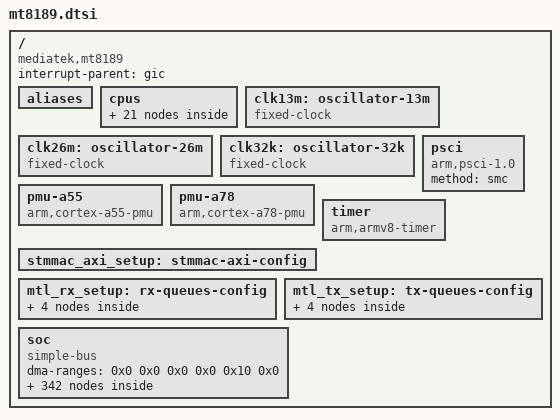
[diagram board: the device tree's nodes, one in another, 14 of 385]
// SPDX-License-Identifier: GPL-2.0+
/*
 * Copyright (c) 2024 MediaTek Inc.
 *
 */

/dts-v1/;
#include <dt-bindings/interrupt-controller/arm-gic.h>
#include <dt-bindings/interrupt-controller/irq.h>
#include <dt-bindings/memory/mediatek,mt8189-memory-port.h>
#include <dt-bindings/phy/phy.h>
#include <dt-bindings/reset/ti-syscon.h>
#include <dt-bindings/clock/mediatek,mt8189-clk.h>
#include <dt-bindings/spmi/spmi.h>
#include <dt-bindings/power/mediatek,mt8189-power.h>
#include <dt-bindings/gce/mt8189-gce.h>
#include <dt-bindings/thermal/thermal.h>

/ {
	compatible = "mediatek,mt8189";
	interrupt-parent = <&gic>;
	#address-cells = <2>;
	#size-cells = <2>;

	aliases {
		i2c0 = &i2c0;
		i2c1 = &i2c1;
		i2c2 = &i2c2;
		i2c3 = &i2c3;
		i2c4 = &i2c4;
		i2c5 = &i2c5;
		i2c6 = &i2c6;
		i2c7 = &i2c7;
		i2c8 = &i2c8;
		gce0 = &gce0;
		gce1 = &gce1;
		ovl0 = &disp_ovl0_4l;
		ovl1 = &disp_ovl1_4l;
		rdma0 = &disp_rdma0;
		rdma1 = &disp_rdma1;
		mmc0 = &mmc0;
		mmc1 = &mmc1;
		mmc2 = &mmc2;
		dvo0 = &disp_dvo0;
		dvo1 = &disp_dvo1;
		dvo2 = &disp_dvo2;
		lvds = &lvds;
	};

	cpus {
		#address-cells = <1>;
		#size-cells = <0>;

		cpu0: cpu@0 {
			device_type = "cpu";
			compatible = "arm,cortex-a55";
			reg = <0x000>;
			enable-method = "psci";
			clock-frequency = <2000000000>;
			capacity-dmips-mhz = <282>;
			performance-domains = <&performance 0>;
			cpu-idle-states = <&cpuoff_l>;
			#cooling-cells = <2>;
		};

		cpu1: cpu@100 {
			device_type = "cpu";
			compatible = "arm,cortex-a55";
			reg = <0x100>;
			enable-method = "psci";
			clock-frequency = <2000000000>;
			capacity-dmips-mhz = <282>;
			performance-domains = <&performance 0>;
			cpu-idle-states = <&cpuoff_l>;
			#cooling-cells = <2>;
		};

		cpu2: cpu@200 {
			device_type = "cpu";
			compatible = "arm,cortex-a55";
			reg = <0x200>;
			enable-method = "psci";
			clock-frequency = <2000000000>;
			capacity-dmips-mhz = <282>;
			performance-domains = <&performance 0>;
			cpu-idle-states = <&cpuoff_l>;
			#cooling-cells = <2>;
		};

		cpu3: cpu@300 {
			device_type = "cpu";
			compatible = "arm,cortex-a55";
			reg = <0x300>;
			enable-method = "psci";
			clock-frequency = <2000000000>;
			capacity-dmips-mhz = <282>;
			performance-domains = <&performance 0>;
			cpu-idle-states = <&cpuoff_l>;
			#cooling-cells = <2>;
		};

		cpu4: cpu@400 {
			device_type = "cpu";
			compatible = "arm,cortex-a55";
			reg = <0x400>;
			enable-method = "psci";
			clock-frequency = <2000000000>;
			capacity-dmips-mhz = <282>;
			performance-domains = <&performance 0>;
			cpu-idle-states = <&cpuoff_l>;
			#cooling-cells = <2>;
		};

		cpu5: cpu@500 {
			device_type = "cpu";
			compatible = "arm,cortex-a55";
			reg = <0x500>;
			enable-method = "psci";
			clock-frequency = <2000000000>;
			capacity-dmips-mhz = <282>;
			performance-domains = <&performance 0>;
			cpu-idle-states = <&cpuoff_l>;
			#cooling-cells = <2>;
		};

		cpu6: cpu@600 {
			device_type = "cpu";
			compatible = "arm,cortex-a78";
			reg = <0x600>;
			enable-method = "psci";
			clock-frequency = <2600000000>;
			capacity-dmips-mhz = <1024>;
			performance-domains = <&performance 1>;
			cpu-idle-states = <&cpuoff_b>;
			#cooling-cells = <2>;
		};

		cpu7: cpu@700 {
			device_type = "cpu";
			compatible = "arm,cortex-a78";
			reg = <0x700>;
			enable-method = "psci";
			clock-frequency = <2600000000>;
			capacity-dmips-mhz = <1024>;
			performance-domains = <&performance 1>;
			cpu-idle-states = <&cpuoff_b>;
			#cooling-cells = <2>;
		};

		cpu-map {
			cluster0 {
				core0 {
					cpu = <&cpu0>;
				};

				core1 {
					cpu = <&cpu1>;
				};

				core2 {
					cpu = <&cpu2>;
				};

				core3 {
					cpu = <&cpu3>;
				};

				core4 {
					cpu = <&cpu4>;
				};

				core5 {
					cpu = <&cpu5>;
				};

				core6 {
					cpu = <&cpu6>;
				};

				core7 {
					cpu = <&cpu7>;
				};
			};
		};

		idle-states {
			entry-method = "arm,psci";
			cpuoff_l: cpuoff-l {
				compatible = "arm,idle-state";
				arm,psci-suspend-param = <0x00010000>;
				local-timer-stop;
				entry-latency-us = <25>;
				exit-latency-us = <57>;
				min-residency-us = <5700>;
			};

			cpuoff_b: cpuoff-b {
				compatible = "arm,idle-state";
				arm,psci-suspend-param = <0x00010000>;
				local-timer-stop;
				entry-latency-us = <35>;
				exit-latency-us = <82>;
				min-residency-us = <1890>;
			};
		};
	};

	clk13m: oscillator-13m {
		compatible = "fixed-clock";
		#clock-cells = <0>;
		clock-frequency = <13000000>;
		clock-output-names = "clk13m";
	};

	clk26m: oscillator-26m {
		compatible = "fixed-clock";
		#clock-cells = <0>;
		clock-frequency = <26000000>;
		clock-output-names = "clk26m";
	};

	clk32k: oscillator-32k {
		compatible = "fixed-clock";
		#clock-cells = <0>;
		clock-frequency = <32768>;
		clock-output-names = "clk32k";
	};

	pmu-a55 {
		compatible = "arm,cortex-a55-pmu";
		interrupt-parent = <&gic>;
		interrupts = <GIC_PPI 7 IRQ_TYPE_LEVEL_HIGH &ppi_cluster0>;
	};

	pmu-a78 {
		compatible = "arm,cortex-a78-pmu";
		interrupt-parent = <&gic>;
		interrupts = <GIC_PPI 7 IRQ_TYPE_LEVEL_HIGH &ppi_cluster1>;
	};

	psci {
		compatible = "arm,psci-1.0";
		method = "smc";
	};

	timer: timer {
		compatible = "arm,armv8-timer";
		interrupt-parent = <&gic>;
		interrupts = <GIC_PPI 13 IRQ_TYPE_LEVEL_HIGH 0>,
			     <GIC_PPI 14 IRQ_TYPE_LEVEL_HIGH 0>,
			     <GIC_PPI 11 IRQ_TYPE_LEVEL_HIGH 0>,
			     <GIC_PPI 10 IRQ_TYPE_LEVEL_HIGH 0>;
		clock-frequency = <13000000>;
	};

	stmmac_axi_setup: stmmac-axi-config {
		snps,wr-osr-lmt = <0x7>;
		snps,rd-osr-lmt = <0x7>;
		snps,blen = <0 0 0 0 16 8 4>;
	};

	mtl_rx_setup: rx-queues-config {
		snps,rx-queues-to-use = <4>;
		snps,rx-sched-sp;
		queue0 {
			snps,dcb-algorithm;
			snps,map-to-dma-channel = <0x0>;
		};
		queue1 {
			snps,dcb-algorithm;
			snps,map-to-dma-channel = <0x0>;
		};
		queue2 {
			snps,dcb-algorithm;
			snps,map-to-dma-channel = <0x0>;
		};
		queue3 {
			snps,dcb-algorithm;
			snps,map-to-dma-channel = <0x0>;
		};
	};

	mtl_tx_setup: tx-queues-config {
		snps,tx-queues-to-use = <4>;
		snps,tx-sched-wrr;
		queue0 {
			snps,weight = <0x10>;
			snps,dcb-algorithm;
			snps,priority = <0x0>;
		};
		queue1 {
			snps,weight = <0x11>;
			snps,dcb-algorithm;
			snps,priority = <0x1>;
		};
		queue2 {
			snps,weight = <0x12>;
			snps,dcb-algorithm;
			snps,priority = <0x2>;
		};
		queue3 {
			snps,weight = <0x13>;
			snps,dcb-algorithm;
			snps,priority = <0x3>;
		};
	};

	soc {
		#address-cells = <2>;
		#size-cells = <2>;
		compatible = "simple-bus";
		ranges;
		dma-ranges = <0x0 0x0 0x0 0x0 0x10 0x0>;

		performance: performance-controller@108d68 {
			compatible = "mediatek,cpufreq-hw";
			reg = <0 0x00108d78 0 0x120>,
			      <0 0x00108e98 0 0x120>;
			reg-names = "performance-domain0",
				    "performance-domain1";
			#performance-domain-cells = <1>;
		};

		gic: interrupt-controller@c000000 {
			compatible = "arm,gic-v3";
			#interrupt-cells = <4>;
			#redistributor-regions = <1>;
			interrupt-parent = <&gic>;
			interrupt-controller;
			reg = <0 0x0c000000 0 0x40000>,
			      <0 0x0c040000 0 0x200000>;
			interrupts = <GIC_PPI 9 IRQ_TYPE_LEVEL_HIGH 0>;

			ppi-partitions {
				ppi_cluster0: interrupt-partition-0 {
					affinity = <&cpu0 &cpu1 &cpu2 &cpu3 &cpu4 &cpu5>;
				};

				ppi_cluster1: interrupt-partition-1 {
					affinity = <&cpu6 &cpu7>;
				};
			};
		};

		dbgao_clk: syscon@d01a000 {
			compatible = "mediatek,mt8189-dbg_ao", "syscon";
			reg = <0 0xd01a000 0 0x1000>;
			#clock-cells = <1>;
		};

		dem_clk: syscon@d0a0000 {
			compatible = "mediatek,mt8189-dem", "syscon";
			reg = <0 0xd0a0000 0 0x1000>;
			#clock-cells = <1>;
		};

		topckgen_clk: syscon@10000000 {
			compatible = "mediatek,mt8189-topckgen", "syscon";
			reg = <0 0x10000000 0 0x1000>;
			#clock-cells = <1>;
		};

		infracfg_ao_clk: syscon@10001000 {
			compatible = "mediatek,mt8189-infra_ao", "syscon";
			reg = <0 0x10001000 0 0x1000>;
			#clock-cells = <1>;
		};

		pio: pinctrl@10005000 {
			compatible = "mediatek,mt8189-pinctrl";
			reg = <0 0x10005000 0 0x1000>,
			      <0 0x11b50000 0 0x1000>,
			      <0 0x11c50000 0 0x1000>,
			      <0 0x11c60000 0 0x1000>,
			      <0 0x11d20000 0 0x1000>,
			      <0 0x11d30000 0 0x1000>,
			      <0 0x11d40000 0 0x1000>,
			      <0 0x11e20000 0 0x1000>,
			      <0 0x11e30000 0 0x1000>,
			      <0 0x11f20000 0 0x1000>;
			reg-names = "gpio_base",
						"iocfg_lm_base",
						"iocfg_rb0_base",
						"iocfg_rb1_base",
						"iocfg_bm0_base",
						"iocfg_bm1_base",
						"iocfg_bm2_base",
						"iocfg_lt0_base",
						"iocfg_lt1_base",
						"iocfg_rt_base";
			gpio-controller;
			#gpio-cells = <2>;
			gpio-ranges = <&pio 0 0 182>;
			interrupt-controller;
			#interrupt-cells = <2>;
			mediatek,eint = <&eint>;
		};

		apmixedsys_clk: syscon@1000c000 {
			compatible = "mediatek,mt8189-apmixedsys", "syscon";
			reg = <0 0x1000c000 0 0x1000>;
			#clock-cells = <1>;
		};

		usb_dp_selector: usb-dp-selector@10011018 {
			compatible = "mediatek,usb_dp_selector";
			reg = <0 0x10011018 0 0x4>;
			reg-names = "usb_dp_reg";
			mediatek,uds-ver = <3>;
			status = "disabled";
		};

		usb_dp_selector_p3: usb-dp-selector@10011034 {
			compatible = "mediatek,usb_dp_selector";
			reg = <0 0x10011034 0 0x4>;
			reg-names = "usb_dp_reg";
			mediatek,uds-ver = <4>;
			status = "disabled";
		};

		emicfg_ao_mem_clk: syscon@10270000 {
			compatible = "mediatek,mt8189-emicfg_ao_mem", "syscon";
			reg = <0 0x10270000 0 0x1000>;
		};

		infra_iommu_m4: infra-iommu@10330000 {
			compatible = "mediatek,mt8189-iommu-infra";
			reg = <0 0x10330000 0 0x1000>;
			interrupts = <GIC_SPI 553 IRQ_TYPE_LEVEL_HIGH 0>;
			clocks = <&clk26m>;
			clock-names = "bclk";
			#iommu-cells = <1>;
		};

		infra_iommu_m7: infra-iommu@1033a000 {
			compatible = "mediatek,mt8189-iommu-infra";
			reg = <0 0x1033a000 0 0x1000>;
			interrupts = <GIC_SPI 543 IRQ_TYPE_LEVEL_HIGH 0>;
			clocks = <&clk26m>;
			clock-names = "bclk";
			#iommu-cells = <1>;
		};

		pericfg_ao_clk: syscon@11036000 {
			compatible = "mediatek,mt8189-peri_ao", "syscon";
			reg = <0 0x11036000 0 0x1000>;
			#clock-cells = <1>;
		};

		uart0: serial@11001000 {
			compatible = "mediatek,mt6577-uart";
			reg = <0 0x11001000 0 0x1000>;
			interrupts = <GIC_SPI 397 IRQ_TYPE_LEVEL_HIGH 0>;
			clocks = <&clk26m>, <&pericfg_ao_clk CLK_PERAO_UART0>;
			clock-names = "baud", "bus";
			status = "disabled";
		};

		uart1: serial@11002000 {
			compatible = "mediatek,mt6577-uart";
			reg = <0 0x11002000 0 0x1000>;
			interrupts = <GIC_SPI 398 IRQ_TYPE_LEVEL_HIGH 0>;
			clocks = <&clk26m>, <&pericfg_ao_clk CLK_PERAO_UART1>;
			clock-names = "baud", "bus";
			dmas = <&apdma 2 &apdma 3>;
			dma-names = "tx", "rx";
			uart-line = <1>;
			status = "disabled";
		};

		uart2: serial@11003000 {
			compatible = "mediatek,mt6577-uart";
			reg = <0 0x11003000 0 0x1000>;
			interrupts = <GIC_SPI 399 IRQ_TYPE_LEVEL_HIGH 0>;
			clocks = <&clk26m>, <&pericfg_ao_clk CLK_PERAO_UART2>;
			clock-names = "baud", "bus";
			dmas = <&apdma 4 &apdma 5>;
			dma-names = "tx", "rx";
			uart-line = <2>;
			status = "disabled";
		};

		uart3: serial@11004000 {
			compatible = "mediatek,mt6577-uart";
			reg = <0 0x11004000 0 0x1000>;
			interrupts = <GIC_SPI 457 IRQ_TYPE_LEVEL_HIGH 0>;
			clocks = <&clk26m>, <&pericfg_ao_clk CLK_PERAO_UART3>;
			clock-names = "baud", "bus";
			dmas = <&apdma 6 &apdma 7>;
			dma-names = "tx", "rx";
			uart-line = <3>;
			status = "disabled";
		};

		afe_clk: syscon@11050000 {
			compatible = "mediatek,mt8189-audiosys", "syscon";
			reg = <0 0x11050000 0 0x1000>;
			#clock-cells = <1>;
		};

		afe: mt8189-afe-pcm@11050000 {
			compatible = "mediatek,mt8189-afe-pcm";
			reg = <0 0x11050000 0 0x10000>;
			interrupts = <GIC_SPI 392 IRQ_TYPE_LEVEL_HIGH 0>;
			power-domains = <&scpsys MT8189_POWER_DOMAIN_AUDIO>;
			memory-region = <&afe_dma_mem_reserved>;
			clocks = <&topckgen_clk CLK_TOP_AUD_INTBUS_SEL>,
				 <&topckgen_clk CLK_TOP_AUD_ENGEN1_SEL>,
				 <&topckgen_clk CLK_TOP_AUD_ENGEN2_SEL>,
				 <&topckgen_clk CLK_TOP_AUDIO_H_SEL>,
				 <&topckgen_clk CLK_TOP_APLL1>,
				 <&topckgen_clk CLK_TOP_APLL2>,
				 <&topckgen_clk CLK_TOP_APLL1_D4>,
				 <&topckgen_clk CLK_TOP_APLL2_D4>,
				 <&topckgen_clk CLK_TOP_APLL12_CK_DIV_I2SIN0>,
				 <&topckgen_clk CLK_TOP_APLL12_CK_DIV_I2SIN1>,
				 <&topckgen_clk CLK_TOP_APLL12_CK_DIV_I2SOUT0>,
				 <&topckgen_clk CLK_TOP_APLL12_CK_DIV_I2SOUT1>,
				 <&topckgen_clk CLK_TOP_APLL12_CK_DIV_FMI2S>,
				 <&topckgen_clk CLK_TOP_APLL12_CK_DIV_TDMOUT_M>,
				 <&topckgen_clk CLK_TOP_APLL12_CK_DIV_TDMOUT_B>,
				 <&topckgen_clk CLK_TOP_AUD_1_SEL>,
				 <&topckgen_clk CLK_TOP_AUD_2_SEL>,
				 <&topckgen_clk CLK_TOP_APLL_I2SIN0_MCK_SEL>,
				 <&topckgen_clk CLK_TOP_APLL_I2SIN1_MCK_SEL>,
				 <&topckgen_clk CLK_TOP_APLL_I2SOUT0_MCK_SEL>,
				 <&topckgen_clk CLK_TOP_APLL_I2SOUT1_MCK_SEL>,
				 <&topckgen_clk CLK_TOP_APLL_FMI2S_MCK_SEL>,
				 <&topckgen_clk CLK_TOP_APLL_TDMOUT_MCK_SEL>,
				 <&topckgen_clk CLK_TOP_TCK_26M_MX9>,
				 <&pericfg_ao_clk CLK_PERAO_AUDIO0>,
				 <&pericfg_ao_clk CLK_PERAO_AUDIO1>,
				 <&pericfg_ao_clk CLK_PERAO_AUDIO2>;
			clock-names = "top_aud_intbus",
				      "top_aud_eng1",
				      "top_aud_eng2",
				      "top_aud_h",
				      "apll1",
				      "apll2",
				      "apll1_d4",
				      "apll2_d4",
				      "apll12_div_i2sin0",
				      "apll12_div_i2sin1",
				      "apll12_div_i2sout0",
				      "apll12_div_i2sout1",
				      "apll12_div_fmi2s",
				      "apll12_div_tdmout_m",
				      "apll12_div_tdmout_b",
				      "top_apll1",
				      "top_apll2",
				      "top_i2sin0",
				      "top_i2sin1",
				      "top_i2sout0",
				      "top_i2sout1",
				      "top_fmi2s",
				      "top_dptx",
				      "clk26m",
				      "aud_slv_ck_peri",
				      "aud_mst_ck_peri",
				      "aud_intbus_ck_peri";
			mediatek,apmixedsys = <&apmixedsys_clk>;
			mediatek,topckgen = <&topckgen_clk>;
			status = "disabled";
		};

		sound: sound {
			mediatek,platform = <&afe>;
			status = "disabled";
		};

		sspm: sspm@1c300000 {
			compatible = "mediatek,sspm";
			reg = <0 0x1c300000 0 0x2c000>,
			      <0 0x1c340000 0 0x10000>,
			      <0 0x1c380000 0 0x80>;

			reg-names = "sspm_base",
				    "cfgreg",
				    "mbox_share";

			interrupts = <GIC_SPI 508 IRQ_TYPE_LEVEL_HIGH 0>;
			interrupt-names = "ipc";
			memory-region = <&sspm_resv_mem>;
			sspm-res-ram-start = <0x0>;
			sspm-res-ram-size = <0x110000>; /* 1M + 64K */

			sspm-share-region-base = <0x24000>; /* 144K */
			sspm-share-region-size = <0x8000>; /* 32K */
			status = "disabled";
		};

		ssram@1c350000 {
			compatible = "mmio-sram";
			reg = <0x0 0x1c350000 0x0 0x80>;

			#address-cells = <1>;
			#size-cells = <1>;
			ranges = <0 0x0 0x1c350000 0x80>;

			scmi_tx_shmem: tiny-mbox@0 {
				compatible = "arm,scmi-shmem";
				reg = <0x0 0x80>;
			};
		};

		ssram@1c360000 {
			compatible = "mmio-sram";
			reg = <0x0 0x1c360000 0x0 0x80>;

			#address-cells = <1>;
			#size-cells = <1>;
			ranges = <0 0x0 0x1c360000 0x80>;

			scmi_rx_shmem: tiny-mbox@1 {
				compatible = "arm,scmi-shmem";
				reg = <0x0 0x80>;
			};
		};

		tinysys_mbox: tinysys-mbox@1c351000 {
			compatible = "mediatek,tinysys_mbox";
			reg = <0 0x1c351000 0 0x1000>,
			      <0 0x1c361000 0 0x1000>;
			/* for profiling */
			shmem = <&scmi_tx_shmem>, <&scmi_rx_shmem>;
			interrupts = <GIC_SPI 509 IRQ_TYPE_LEVEL_HIGH 0>,
				     <GIC_SPI 510 IRQ_TYPE_LEVEL_HIGH 0>;
			#mbox-cells = <1>;
		};

		ssusb: usb0@11201000 {
			compatible = "mediatek,mtu3";
			reg = <0 0x11201000 0 0x2e00>,
			      <0 0x11203e00 0 0x0100>;
			reg-names = "mac", "ippc";
			interrupts = <GIC_SPI 384 IRQ_TYPE_LEVEL_HIGH 0>;
			phy-cells = <1>;
			phys = <&u2port0 PHY_TYPE_USB2>,
			       <&u3port0 PHY_TYPE_USB3>;
			assigned-clocks = <&topckgen_clk CLK_TOP_USB_TOP_P0_SEL>;
			assigned-clock-parents = <&topckgen_clk CLK_TOP_UNIVPLL_D5_D4>;
			clocks = <&pericfg_ao_clk CLK_PERAO_SSUSB0_XHCI>,
				 <&pericfg_ao_clk CLK_PERAO_SSUSB0_SYS>,
				 <&pericfg_ao_clk CLK_PERAO_SSUSB0_H>,
				 <&pericfg_ao_clk CLK_PERAO_SSUSB0_F>,
				 <&pericfg_ao_clk CLK_PERAO_SSUSB0_REF>,
				 <&pericfg_ao_clk CLK_PERAO_SSUSB0_FRMCNT>;
			clock-names = "xhci_ck",
				      "sys_ck",
				      "mcu_ck",
				      "dma_ck",
				      "ref_ck",
				      "frmcnt_ck";
			#address-cells = <2>;
			#size-cells = <2>;
			ranges;
			dr_mode = "otg";
			mediatek,syscon-wakeup = <&pericfg_ao_clk 0x214 103>;
			usb-role-switch;
			xhci0: xhci0@11200000 {
				compatible = "mediatek,mtk-xhci";
				reg = <0 0x11200000 0 0x1000>;
				reg-names = "mac";
				interrupts = <GIC_SPI 385 IRQ_TYPE_LEVEL_HIGH 0>;
				assigned-clocks = <&topckgen_clk CLK_TOP_USB_XHCI_P0_SEL>;
				assigned-clock-parents = <&topckgen_clk CLK_TOP_UNIVPLL_D5_D4>;
				clocks = <&pericfg_ao_clk CLK_PERAO_SSUSB0_XHCI>,
					 <&pericfg_ao_clk CLK_PERAO_SSUSB0_SYS>,
					 <&pericfg_ao_clk CLK_PERAO_SSUSB0_H>,
					 <&pericfg_ao_clk CLK_PERAO_SSUSB0_F>,
					 <&pericfg_ao_clk CLK_PERAO_SSUSB0_REF>;
				clock-names = "xhci_ck",
					      "sys_ck",
					      "mcu_ck",
					      "dma_ck",
					      "ref_ck";
			};
		};

		xhci1: xhci1@11210000 {
			compatible = "mediatek,mtk-xhci";
			reg = <0 0x11210000 0 0x1000>,
			      <0 0x11213e00 0 0x0100>;
			reg-names = "mac", "ippc";
			interrupts = <GIC_SPI 386 IRQ_TYPE_LEVEL_HIGH 0>;
			phy-cells = <1>;
			phys = <&u2port1 PHY_TYPE_USB2>;
			assigned-clocks = <&topckgen_clk CLK_TOP_USB_TOP_P1_SEL>,
					  <&topckgen_clk CLK_TOP_USB_XHCI_P1_SEL>;
			assigned-clock-parents = <&topckgen_clk CLK_TOP_UNIVPLL_D5_D4>,
						 <&topckgen_clk CLK_TOP_UNIVPLL_D5_D4>;
			clocks = <&pericfg_ao_clk CLK_PERAO_SSUSB1_XHCI>,
				 <&pericfg_ao_clk CLK_PERAO_SSUSB1_SYS>,
				 <&pericfg_ao_clk CLK_PERAO_SSUSB1_H>,
				 <&pericfg_ao_clk CLK_PERAO_SSUSB1_F>,
				 <&pericfg_ao_clk CLK_PERAO_SSUSB1_REF>,
				 <&pericfg_ao_clk CLK_PERAO_SSUSB1_FRMCNT>;
			clock-names = "xhci_ck",
				      "sys_ck",
				      "mcu_ck",
				      "dma_ck",
				      "ref_ck",
				      "frmcnt_ck";
			power-domains = <&scpsys MT8189_POWER_DOMAIN_SSUSB>;
			mediatek,syscon-wakeup = <&pericfg_ao_clk 0x21c 107>;
			#address-cells = <2>;
			#size-cells = <2>;
			status = "disabled";
		};

		xhci2: xhci2@11220000 {
			compatible = "mediatek,mtk-xhci";
			reg = <0 0x11220000 0 0x1000>,
			      <0 0x11223e00 0 0x0100>;
			reg-names = "mac", "ippc";
			interrupts = <GIC_SPI 472 IRQ_TYPE_LEVEL_HIGH 0>;
			phy-cells = <1>;
			phys = <&u2port2 PHY_TYPE_USB2>;
			assigned-clocks = <&topckgen_clk CLK_TOP_USB_TOP_P2_SEL>,
					  <&topckgen_clk CLK_TOP_USB_XHCI_P2_SEL>;
			assigned-clock-parents = <&topckgen_clk CLK_TOP_UNIVPLL_D5_D4>,
						 <&topckgen_clk CLK_TOP_UNIVPLL_D5_D4>;
			clocks = <&pericfg_ao_clk CLK_PERAO_SSUSB2_XHCI>,
				 <&pericfg_ao_clk CLK_PERAO_SSUSB2_SYS>,
				 <&pericfg_ao_clk CLK_PERAO_SSUSB2_H>,
				 <&pericfg_ao_clk CLK_PERAO_SSUSB2_F>,
				 <&pericfg_ao_clk CLK_PERAO_SSUSB2_REF>,
				 <&pericfg_ao_clk CLK_PERAO_SSUSB2_FRMCNT>;
			clock-names = "xhci_ck",
				      "sys_ck",
				      "mcu_ck",
				      "dma_ck",
				      "ref_ck",
				      "frmcnt_ck";
			power-domains = <&scpsys MT8189_POWER_DOMAIN_SSUSB>;
			mediatek,syscon-wakeup = <&pericfg_ao_clk 0x27c 107>;
			#address-cells = <2>;
			#size-cells = <2>;
			status = "disabled";
		};

		xhci3: xhci3@11260000 {
			compatible = "mediatek,mtk-xhci";
			reg = <0 0x11260000 0 0x2e00>,
			      <0 0x11263e00 0 0x0100>;
			reg-names = "mac", "ippc";
			interrupts = <GIC_SPI 473 IRQ_TYPE_LEVEL_HIGH 0>;
			phy-cells = <1>;
			phys = <&u2port3 PHY_TYPE_USB2>,
			       <&u3port3 PHY_TYPE_USB3>;
			assigned-clocks = <&topckgen_clk CLK_TOP_USB_TOP_P3_SEL>,
					  <&topckgen_clk CLK_TOP_USB_XHCI_P3_SEL>;
			assigned-clock-parents = <&topckgen_clk CLK_TOP_UNIVPLL_D5_D4>,
						 <&topckgen_clk CLK_TOP_UNIVPLL_D5_D4>;
			clocks = <&pericfg_ao_clk CLK_PERAO_SSUSB3_XHCI>,
				 <&pericfg_ao_clk CLK_PERAO_SSUSB3_SYS>,
				 <&pericfg_ao_clk CLK_PERAO_SSUSB3_H>,
				 <&pericfg_ao_clk CLK_PERAO_SSUSB3_F>,
				 <&pericfg_ao_clk CLK_PERAO_SSUSB3_REF>,
				 <&pericfg_ao_clk CLK_PERAO_SSUSB3_FRMCNT>;
			clock-names = "xhci_ck",
				      "sys_ck",
				      "mcu_ck",
				      "dma_ck",
				      "ref_ck",
				      "frmcnt_ck";
			power-domains = <&scpsys MT8189_POWER_DOMAIN_SSUSB>;
			mediatek,syscon-wakeup = <&pericfg_ao_clk 0x284 107>;
			#address-cells = <2>;
			#size-cells = <2>;
			status = "disabled";
		};

		xhci4: xhci4@11270000 {
			compatible = "mediatek,mtk-xhci";
			reg = <0 0x11270000 0 0x1000>,
			      <0 0x11273e00 0 0x0100>;
			reg-names = "mac", "ippc";
			interrupts = <GIC_SPI 474 IRQ_TYPE_LEVEL_HIGH 0>;
			phy-cells = <1>;
			phys = <&u2port4 PHY_TYPE_USB2>;
			assigned-clocks = <&topckgen_clk CLK_TOP_USB_TOP_P4_SEL>,
					  <&topckgen_clk CLK_TOP_USB_XHCI_P4_SEL>;
			assigned-clock-parents = <&topckgen_clk CLK_TOP_UNIVPLL_D5_D4>,
						 <&topckgen_clk CLK_TOP_UNIVPLL_D5_D4>;
			clocks = <&pericfg_ao_clk CLK_PERAO_SSUSB4_XHCI>,
				 <&pericfg_ao_clk CLK_PERAO_SSUSB4_SYS>,
				 <&pericfg_ao_clk CLK_PERAO_SSUSB4_H>,
				 <&pericfg_ao_clk CLK_PERAO_SSUSB4_F>,
				 <&pericfg_ao_clk CLK_PERAO_SSUSB4_REF>,
				 <&pericfg_ao_clk CLK_PERAO_SSUSB4_FRMCNT>;
			clock-names = "xhci_ck",
				      "sys_ck",
				      "mcu_ck",
				      "dma_ck",
				      "ref_ck",
				      "frmcnt_ck";
			#address-cells = <2>;
			#size-cells = <2>;
			mediatek,syscon-wakeup = <&pericfg_ao_clk 0x28c 107>;
			status = "disabled";
		};

		mmc0: mmc@11230000 {
			compatible = "mediatek,mt8196-mmc";
			reg = <0 0x11230000 0 0x10000>,
			      <0 0x11e70000 0 0x1000>;
			interrupts = <GIC_SPI 387 IRQ_TYPE_LEVEL_HIGH 0>;
			clocks = <&topckgen_clk CLK_TOP_MSDC50_0_SEL>,
				<&topckgen_clk CLK_TOP_MSDC50_0_HCLK_SEL>,
				<&pericfg_ao_clk CLK_PERAO_MSDC0>,
				<&pericfg_ao_clk CLK_PERAO_MSDC0_H>,
				<&topckgen_clk CLK_TOP_MSDC50_0_SEL>,
				<&pericfg_ao_clk CLK_PERAO_MSDC0_SLV_H>,
				<&pericfg_ao_clk CLK_PERAO_MSDC0_MST_F>;
			clock-names = "source", "bus_clk", "source_cg", "hclk",
					"crypto", "pclk_cg", "axi_cg";
			status = "disabled";
		};

		mmc1: mmc@11240000 {
			compatible = "mediatek,mt8196-mmc";
			reg = <0 0x11240000 0 0x1000>,
			      <0 0x11d80000 0 0x1000>;
			interrupts = <GIC_SPI 388 IRQ_TYPE_LEVEL_HIGH 0>;
			clocks = <&topckgen_clk CLK_TOP_MSDC30_1_SEL>,
				<&topckgen_clk CLK_TOP_MSDC30_1_HCLK_SEL>,
				<&pericfg_ao_clk CLK_PERAO_MSDC1>,
				<&pericfg_ao_clk CLK_PERAO_MSDC1_H>,
				<&pericfg_ao_clk CLK_PERAO_MSDC1_SLV_H>,
				<&pericfg_ao_clk CLK_PERAO_MSDC1_MST_F>;
			clock-names = "source", "bus_clk", "source_cg", "hclk",
					"pclk_cg", "axi_cg";
			status = "disabled";
		};

		mmc2: mmc@11250000 {
			compatible = "mediatek,mt8196-mmc";
			reg = <0 0x11250000 0 0x1000>,
			      <0 0x11f70000 0 0x1000>;
			interrupts = <GIC_SPI 389 IRQ_TYPE_LEVEL_HIGH 0>;
			clocks = <&topckgen_clk CLK_TOP_MSDC30_2_SEL>,
				<&topckgen_clk CLK_TOP_MSDC_MACRO_2P_SEL>,
				<&pericfg_ao_clk CLK_PERAO_MSDC2_H>,
				<&pericfg_ao_clk CLK_PERAO_MSDC2>,
				<&pericfg_ao_clk CLK_PERAO_MSDC2_MST_F>,
				<&pericfg_ao_clk CLK_PERAO_MSDC2_SLV_H>;
			clock-names = "source", "bus_clk", "hclk", "source_cg",
					"pclk_cg", "sys_cg";
			status = "disabled";
		};

		nor_flash: spi@11018000 {
			compatible = "mediatek,mt8186-nor",
						"mediatek,mt8189-nor";
			reg = <0 0x11018000 0 0x1000>;
			clocks = <&topckgen_clk CLK_TOP_SFLASH_SEL>,
				 <&pericfg_ao_clk CLK_PERAO_SFLASH>,
				 <&pericfg_ao_clk CLK_PERAO_SFLASH_F>,
				 <&pericfg_ao_clk CLK_PERAO_SFLASH_H>,
				 <&pericfg_ao_clk CLK_PERAO_SFLASH_P>;
			clock-names = "spi", "sf", "axi_f", "axi_h", "axi_p";
			assigned-clocks = <&topckgen_clk CLK_TOP_SFLASH_SEL>;
			assigned-clock-parents = <&topckgen_clk CLK_TOP_UNIVPLL_D6_D8>;
			interrupts = <GIC_SPI 390 IRQ_TYPE_LEVEL_HIGH 0>;
			#address-cells = <1>;
			#size-cells = <0>;
			status = "disabled";
		};

		ufsphy: ufsphy@112a0000 {
			compatible = "mediatek,mt8183-ufsphy";
			reg = <0 0x112a0000 0 0x10000>;
			#phy-cells = <0>;
			mphy-ver = <1>;
			status = "disabled";
		};

		ufshci: ufshci@112b0000 {
			compatible = "mediatek,mt8183-ufshci";
			reg = <0 0x112b0000 0 0x2300>;
			phys = <&ufsphy>;
			interrupts = <GIC_SPI 393 IRQ_TYPE_LEVEL_HIGH 0>;

			clocks =
				<&topckgen_clk CLK_TOP_U_SEL>,
				<&topckgen_clk CLK_TOP_AES_UFSFDE_SEL>,
				<&topckgen_clk CLK_TOP_U_MBIST_SEL>,
				<&ufscfg_ao_reg_clk CLK_UFSCFG_AO_REG_UNIPRO_TX_SYM>,
				<&ufscfg_ao_reg_clk CLK_UFSCFG_AO_REG_UNIPRO_RX_SYM0>,
				<&ufscfg_ao_reg_clk CLK_UFSCFG_AO_REG_UNIPRO_RX_SYM1>,
				<&ufscfg_ao_reg_clk CLK_UFSCFG_AO_REG_UNIPRO_SYS>,
				<&ufscfg_ao_reg_clk CLK_UFSCFG_AO_REG_U_SAP_CFG>,
				<&ufscfg_ao_reg_clk CLK_UFSCFG_AO_REG_U_PHY_TOP_AHB_S_BUS>,
				<&ufscfg_pdn_reg_clk CLK_UFSCFG_REG_UFSHCI_UFS>,
				<&ufscfg_pdn_reg_clk CLK_UFSCFG_REG_UFSHCI_AES>,
				<&ufscfg_pdn_reg_clk CLK_UFSCFG_REG_UFSHCI_U_AHB>,
				<&ufscfg_pdn_reg_clk CLK_UFSCFG_REG_UFSHCI_U_AXI>;

			clock-names =
				"ufs_sel",
				"ufs_fde",
				"ufs_mbist",
				"unipro_tx_sym",
				"unipro_rx_sym0",
				"unipro_rx_sym1",
				"unipro_sys",
				"unipro_phy_sap",
				"phy_top_ahb_s_bus",
				"ufshci_ufs",
				"ufshci_aes",
				"ufshci_ufs_ahb",
				"ufshci_aes_axi";

			freq-table-hz =
				<0 0>,
				<0 0>,
				<0 0>,
				<0 0>,
				<0 0>,
				<0 0>,
				<0 0>,
				<0 0>,
				<0 0>,
				<0 0>,
				<0 0>,
				<0 0>,
				<0 0>;

			vcc-supply = <&mt6359_vemc_1_ldo_reg>;
			vccq-supply = <&mt6359_vio18_ldo_reg>;
			vccq2-supply = <&mt6359_vufs_ldo_reg>;

			resets =	<&ufscfgpdn_rst 0>,
					<&ufscfgpdn_rst 1>,
					<&ufscfgpdn_rst 2>;
			reset-names =	"unipro_rst",
					"crypto_rst",
					"hci_rst";

			mediatek,ufs-qos;
			mediatek,ufs-mphy-debug;
			mediatek,ufs-disable-mcq;
			mediatek,ufs-rtff-mtcmos;
			mediatek,ufs-bypass-vccqx-lpm;
			status = "disabled";
		};

		ufscfg_ao_reg_clk: syscon@112b8000 {
			compatible = "mediatek,mt8189-ufscfg_ao", "syscon", "simple-mfd";
			reg = <0 0x112b8000 0 0x1000>;
			#clock-cells = <1>;

			ufscfgao_rst: reset-controller {
				compatible = "ti,syscon-reset";
				#reset-cells = <1>;

				ti,reset-bits = <
					/* ufs mphy reset */
					/* 8: mphy */
					0x48  8 0x4c  8 0 0
					(ASSERT_SET | DEASSERT_SET | STATUS_NONE)
					>;
			};
		};

		ufscfg_pdn_reg_clk: syscon@112bb000 {
			compatible = "mediatek,mt8189-ufscfg_pdn", "syscon", "simple-mfd";
			reg = <0 0x112bb000 0 0x1000>;
			#clock-cells = <1>;

			ufscfgpdn_rst: reset-controller {
				compatible = "ti,syscon-reset";
				#reset-cells = <1>;

				ti,reset-bits = <
					/* ufs ufschi/crypto/unipro reset */
					/* 0: unipro */
					0x48  0 0x4c  0 0 0
					(ASSERT_SET | DEASSERT_SET | STATUS_NONE)
					/* 1: ufs-crypto */
					0x48  1 0x4c  1 0 0
					(ASSERT_SET | DEASSERT_SET | STATUS_NONE)
					/* 2: ufshci */
					0x48  2 0x4c  2 0 0
					(ASSERT_SET | DEASSERT_SET | STATUS_NONE)
					>;
			};
		};

		apdma: dma-controller@11300b00 {
			compatible = "mediatek,mt6577-uart-dma";
			reg = <0 0x11300b00 0 0x80>,
			      <0 0x11300b80 0 0x80>,
			      <0 0x11300c00 0 0x80>,
			      <0 0x11300c80 0 0x80>,
			      <0 0x11300d00 0 0x80>,
			      <0 0x11300d80 0 0x80>,
			      <0 0x11300e00 0 0x80>,
			      <0 0x11300e80 0 0x80>;
			interrupts = <GIC_SPI 432 IRQ_TYPE_LEVEL_HIGH 0>,
				     <GIC_SPI 433 IRQ_TYPE_LEVEL_HIGH 0>,
				     <GIC_SPI 434 IRQ_TYPE_LEVEL_HIGH 0>,
				     <GIC_SPI 435 IRQ_TYPE_LEVEL_HIGH 0>,
				     <GIC_SPI 436 IRQ_TYPE_LEVEL_HIGH 0>,
				     <GIC_SPI 437 IRQ_TYPE_LEVEL_HIGH 0>,
				     <GIC_SPI 438 IRQ_TYPE_LEVEL_HIGH 0>,
				     <GIC_SPI 439 IRQ_TYPE_LEVEL_HIGH 0>;
			clocks = <&pericfg_ao_clk CLK_PERAO_DMA_B>;
			clock-names = "apdma";
			dma-requests = <8>;
			#dma-cells = <1>;
		};

		u3phy3: t-phy3@11b00000 {
			compatible = "mediatek,generic-tphy-v2";
			reg = <0 0x11b00000 0 0x700>;
			#address-cells = <2>;
			#size-cells = <2>;
			ranges;

			u2port3: usb2-phy3@11b00000 {
				reg = <0 0x11b00000 0 0x400>;
				clocks = <&topckgen_clk CLK_TOP_USB2_PHY_RF_P3_EN>;
				clock-names = "ref";
				#phy-cells = <1>;
			};

			u3port3: usb3-phy3@11b00700 {
				reg = <0 0x11b00700 0 0x700>;
				clocks = <&topckgen_clk CLK_TOP_USB2_PHY_RF_P3_EN>;
				clock-names = "ref";
				#phy-cells = <1>;
				mediatek,keep-u3-phy-power;
			};
		};

		u2phy4: xs-phy4@11b10000 {
			compatible = "mediatek,xsphy";
			#address-cells = <2>;
			#size-cells = <2>;
			ranges;

			u2port4: usb2-phy4@11b10000 {
				reg = <0 0x11b10000 0 0x400>;
				clocks = <&topckgen_clk CLK_TOP_USB2_PHY_RF_P4_EN>;
				clock-names = "ref";
				#phy-cells = <1>;
			};
		};

		imp_iic_wrap_ws_clk: syscon@11b21000 {
			compatible = "mediatek,mt8189-iic_wrap_ws", "syscon";
			reg = <0 0x11b21000 0 0x1000>;
			#clock-cells = <1>;
		};

		imp_iic_wrap_e_clk: syscon@11c22000 {
			compatible = "mediatek,mt8189-iic_wrap_e", "syscon";
			reg = <0 0x11c22000 0 0x1000>;
			#clock-cells = <1>;
		};

		imp_iic_wrap_s_clk: syscon@11d74000 {
			compatible = "mediatek,mt8189-iic_wrap_s", "syscon";
			reg = <0 0x11d74000 0 0x1000>;
			#clock-cells = <1>;
		};

		u3phy0: xs-phy0@11e80000 {
			compatible = "mediatek,xsphy";
			reg = <0 0x11e83000 0 0x200>;
			#address-cells = <2>;
			#size-cells = <2>;
			ranges;

			u2port0: usb2-phy0@11e80000 {
				reg = <0 0x11e80000 0 0x400>;
				clocks = <&topckgen_clk CLK_TOP_USB2_PHY_RF_P0_EN>;
				clock-names = "ref";
				#phy-cells = <1>;
			};

			u3port0: usb3-phy0@11e83000 {
				reg = <0 0x11e83400 0 0x500>;
				clocks = <&topckgen_clk CLK_TOP_USB2_PHY_RF_P0_EN>;
				clock-names = "ref";
				#phy-cells = <1>;
			};
		};

		u2phy1: xs-phy1@11e90000 {
			compatible = "mediatek,xsphy";
			#address-cells = <2>;
			#size-cells = <2>;
			ranges;

			u2port1: usb2-phy1@11e90000 {
				reg = <0 0x11e90000 0 0x700>;
				clocks = <&topckgen_clk CLK_TOP_USB2_PHY_RF_P1_EN>;
				clock-names = "ref";
				#phy-cells = <1>;
			};
		};

		u2phy2: xs-phy2@11ef0000 {
			compatible = "mediatek,xsphy";
			#address-cells = <2>;
			#size-cells = <2>;
			ranges;

			u2port2: usb2-phy2@11ef0000 {
				reg = <0 0x11ef0000 0 0x400>;
				clocks = <&topckgen_clk CLK_TOP_USB2_PHY_RF_P2_EN>;
				clock-names = "ref";
				#phy-cells = <1>;
			};
		};

		imp_iic_wrap_en_clk: syscon@11f32000 {
			compatible = "mediatek,mt8189-iic_wrap_en", "syscon";
			reg = <0 0x11f32000 0 0x1000>;
			#clock-cells = <1>;
		};

		gpu: gpu@13000000 {
			compatible = "mediatek,mt8189-mali", "arm,mali-valhall-jm";
			reg = <0 0x13000000 0 0x4000>;

			interrupts = <GIC_SPI 271 IRQ_TYPE_LEVEL_HIGH 0>,
				     <GIC_SPI 270 IRQ_TYPE_LEVEL_HIGH 0>,
				     <GIC_SPI 269 IRQ_TYPE_LEVEL_HIGH 0>;
			interrupt-names = "job", "mmu", "gpu";

			clocks = <&mfg_clk CLK_MFG_BG3D>;
			clock-names = "subsys_bg3d";

			operating-points-v2 = <&gpu_opp_table>;
			power-domains = <&scpsys MT8189_POWER_DOMAIN_MFG2>,
					<&scpsys MT8189_POWER_DOMAIN_MFG3>;
			power-domain-names = "core0", "core1";
			#cooling-cells = <2>;
			status = "disabled";

			power-model@0 {
				compatible = "arm,mali-simple-power-model";
				dynamic-coefficient = <1427>;
				static-coefficient = <118279>;
				thermal-zone = "soc_max";
				ts = <6 (-238) 20283 32499>;
			};
			power-model@1 {
				compatible = "arm,mali-tnax-power-model";
				scale = <5>;
			};
		};

		gpu_opp_table: opp-table-gpu {
			compatible = "operating-points-v2";
			opp-shared;

			opp-390000000 {
				opp-hz = /bits/ 64 <390000000>;
				opp-microvolt = <675000>;
			};

			opp-424000000 {
				opp-hz = /bits/ 64 <424000000>;
				opp-microvolt = <681250>;
			};

			opp-458000000 {
				opp-hz = /bits/ 64 <458000000>;
				opp-microvolt = <681250>;
			};

			opp-492000000 {
				opp-hz = /bits/ 64 <492000000>;
				opp-microvolt = <687500>;
			};

			opp-526000000 {
				opp-hz = /bits/ 64 <526000000>;
				opp-microvolt = <687500>;
			};

			opp-560000000 {
				opp-hz = /bits/ 64 <560000000>;
				opp-microvolt = <693750>;
			};

			opp-595000000 {
				opp-hz = /bits/ 64 <595000000>;
				opp-microvolt = <693750>;
			};

			opp-630000000 {
				opp-hz = /bits/ 64 <630000000>;
				opp-microvolt = <700000>;
			};

			opp-665000000 {
				opp-hz = /bits/ 64 <665000000>;
				opp-microvolt = <700000>;
			};

			opp-700000000 {
				opp-hz = /bits/ 64 <700000000>;
				opp-microvolt = <700000>;
			};

			opp-736000000 {
				opp-hz = /bits/ 64 <736000000>;
				opp-microvolt = <718750>;
			};

			opp-772000000 {
				opp-hz = /bits/ 64 <772000000>;
				opp-microvolt = <737500>;
			};

			opp-808000000 {
				opp-hz = /bits/ 64 <808000000>;
				opp-microvolt = <756250>;
			};

			opp-844000000 {
				opp-hz = /bits/ 64 <844000000>;
				opp-microvolt = <775000>;
			};

			opp-880000000 {
				opp-hz = /bits/ 64 <880000000>;
				opp-microvolt = <793750>;
			};

			opp-935000000 {
				opp-hz = /bits/ 64 <935000000>;
				opp-microvolt = <818750>;
			};

			opp-990000000 {
				opp-hz = /bits/ 64 <990000000>;
				opp-microvolt = <850000>;
			};

			opp-1045000000 {
				opp-hz = /bits/ 64 <1045000000>;
				opp-microvolt = <875000>;
			};

			opp-1100000000 {
				opp-hz = /bits/ 64 <1100000000>;
				opp-microvolt = <900000>;
			};
		};

		mfg_clk: syscon@13fbf000 {
			compatible = "mediatek,mt8189-mfgsys", "syscon";
			reg = <0 0x13fbf000 0 0x1000>;
			#clock-cells = <1>;
		};

		dispsys_config_clk: syscon@14000000 {
			compatible = "mediatek,mt8189-dispsys", "syscon";
			reg = <0 0x14000000 0 0x1000>;
			#clock-cells = <1>;
		};

		smi_larb0: smi-larb0@1401c000 {
			compatible = "mediatek,mt8189-smi-larb", "mediatek,smi-larb";
			reg = <0 0x1401c000 0 0x1000>;
			clocks = <&dispsys_config_clk CLK_MM_SMI_LARB>,
				 <&dispsys_config_clk CLK_MM_SMI_LARB>;
			clock-names = "apb", "smi";
			mediatek,larb-id = <SMI_L0_ID>;
			mediatek,smi = <&smi_disp_common>;
			power-domains = <&scpsys MT8189_POWER_DOMAIN_DISP>;
		};

		smi_larb1: smi-larb1@1401d000 {
			compatible = "mediatek,mt8189-smi-larb", "mediatek,smi-larb";
			reg = <0 0x1401d000 0 0x1000>;
			clocks = <&dispsys_config_clk CLK_MM_SMI_LARB>,
				 <&dispsys_config_clk CLK_MM_SMI_LARB>;
			clock-names = "apb", "smi";
			mediatek,larb-id = <SMI_L1_ID>;
			mediatek,smi = <&smi_disp_common>;
			power-domains = <&scpsys MT8189_POWER_DOMAIN_DISP>;
		};

		imgsys1_clk: syscon@15020000 {
			compatible = "mediatek,mt8189-imgsys1", "syscon";
			reg = <0 0x15020000 0 0x1000>;
			#clock-cells = <1>;
		};

		smi_larb9: smi-larb9@1502e000 {
			compatible = "mediatek,mt8189-smi-larb", "mediatek,smi-larb";
			reg = <0 0x1502e000 0 0x1000>;
			clocks = <&imgsys1_clk CLK_IMGSYS1_LARB9>,
				 <&imgsys1_clk CLK_IMGSYS1_LARB9>;
			clock-names = "apb", "smi";
			mediatek,larb-id = <SMI_L9_ID>;
			mediatek,smi = <&smi_img_2x1_sub_comm>;
			power-domains = <&scpsys MT8189_POWER_DOMAIN_ISP_IMG1>;
		};

		smi_img_2x1_sub_comm: smi-img-2x1-sub-comm@1502f000 {
			compatible = "mediatek,mt8189-smi-sub-common",
				     "mediatek,smi-common", "syscon", "mediatek,smi-sub-common";
			reg = <0 0x1502f000 0 0x1000>;
			clocks = <&imgsys1_clk CLK_IMGSYS1_LARB9>,
				 <&imgsys1_clk CLK_IMGSYS1_LARB11>,
				 <&imgsys1_clk CLK_IMGSYS1_GALS>;
			clock-names = "apb", "smi", "gals0";
			mediatek,smi = <&smi_disp_common>;
			mediatek,common-id = <7>;
			power-domains = <&scpsys MT8189_POWER_DOMAIN_ISP_IMG1>;
		};

		imgsys2_clk: syscon@15820000 {
			compatible = "mediatek,mt8189-imgsys2", "syscon";
			reg = <0 0x15820000 0 0x1000>;
			#clock-cells = <1>;
		};

		smi_larb11: smi-larb11@1582e000 {
			compatible = "mediatek,mt8189-smi-larb", "mediatek,smi-larb";
			reg = <0 0x1582e000 0 0x1000>;
			clocks = <&imgsys2_clk CLK_IMGSYS2_LARB9>,
				 <&imgsys2_clk CLK_IMGSYS2_LARB9>;
			clock-names = "apb", "smi";
			mediatek,larb-id = <SMI_L11_ID>;
			mediatek,smi = <&smi_img_2x1_sub_comm>;
			power-domains = <&scpsys MT8189_POWER_DOMAIN_ISP_IMG2>;
		};

		smi_larb4: smi-larb4@1602e000 {
			compatible = "mediatek,mt8189-smi-larb", "mediatek,smi-larb";
			reg = <0 0x1602e000 0 0x1000>;
			clocks = <&vdec_core_clk CLK_VDEC_CORE_LARB_CKEN>,
				 <&vdec_core_clk CLK_VDEC_CORE_LARB_CKEN>;
			clock-names = "apb", "smi";
			mediatek,larb-id = <SMI_L4_ID>;
			mediatek,smi = <&smi_disp_common>;
			power-domains = <&scpsys MT8189_POWER_DOMAIN_VDE0>;
		};

		vdec_core_clk: syscon@1602f000 {
			compatible = "mediatek,mt8189-vdec_core", "syscon";
			reg = <0 0x1602f000 0 0x1000>;
			#clock-cells = <1>;
		};

		venc_gcon_clk: syscon@17000000 {
			compatible = "mediatek,mt8189-venc", "syscon";
			reg = <0 0x17000000 0 0x1000>;
			#clock-cells = <1>;
		};

		smi_larb7: smi-larb7@17010000 {
			compatible = "mediatek,mt8189-smi-larb", "mediatek,smi-larb";
			reg = <0 0x17010000 0 0x1000>;
			clocks = <&venc_gcon_clk CLK_VEN1_CKE0_LARB>,
				 <&venc_gcon_clk CLK_VEN1_CKE0_LARB>;
			clock-names = "apb", "smi";
			mediatek,larb-id = <SMI_L7_ID>;
			mediatek,smi = <&smi_disp_common>;
			power-domains = <&scpsys MT8189_POWER_DOMAIN_VEN0>;
		};

		apu_iommu: iommu@19010000 {
			compatible = "mediatek,mt8189-iommu-apu";
			reg = <0 0x19010000 0 0x1000>;
			interrupts = <GIC_SPI 597 IRQ_TYPE_LEVEL_HIGH 0>;
			clocks = <&clk26m>;
			clock-names = "bclk";
			#iommu-cells = <1>;
		};

		camsys_main_clk: syscon@1a000000 {
			compatible = "mediatek,mt8189-camsys_main", "syscon";
			reg = <0 0x1a000000 0 0x1000>;
			#clock-cells = <1>;
		};

		smi_larb13: smi-larb13@1a001000 {
			compatible = "mediatek,mt8189-smi-larb", "mediatek,smi-larb";
			reg = <0 0x1a001000 0 0x1000>;
			clocks = <&camsys_main_clk CLK_CAM_M_LARB13>,
				 <&camsys_main_clk CLK_CAM_M_LARB13>;
			clock-names = "apb", "smi";
			mediatek,larb-id = <SMI_L13_ID>;
			mediatek,smi = <&smi_cam_4x1_sub_comm>;
			power-domains = <&scpsys MT8189_POWER_DOMAIN_CAM_MAIN>;
		};

		smi_larb14: smi-larb14@1a002000 {
			compatible = "mediatek,mt8189-smi-larb", "mediatek,smi-larb";
			reg = <0 0x1a002000 0 0x1000>;
			clocks = <&camsys_main_clk CLK_CAM_M_LARB14>,
				 <&camsys_main_clk CLK_CAM_M_LARB14>;
			clock-names = "apb", "smi";
			mediatek,larb-id = <SMI_L14_ID>;
			mediatek,smi = <&smi_cam_3x1_sub_comm>;
			power-domains = <&scpsys MT8189_POWER_DOMAIN_CAM_MAIN>;
		};

		smi_cam_3x1_sub_comm: smi-cam-3x1-sub-comm@1a00c000 {
			compatible = "mediatek,mt8189-smi-sub-common", "mediatek,smi-common",
				     "syscon", "mediatek,smi-sub-common";
			reg = <0 0x1a00c000 0 0x1000>;
			clocks = <&camsys_main_clk CLK_CAM_M_CAM2MM_GALS>,
				 <&camsys_main_clk CLK_CAM_M_CAM2MM_GALS>;
			clock-names = "apb", "smi";
			mediatek,common-id = <5>;
			mediatek,smi = <&smi_disp_common>;
			power-domains = <&scpsys MT8189_POWER_DOMAIN_CAM_MAIN>;
		};

		smi_cam_4x1_sub_comm: smi-cam-4x1-sub-comm@1a00d000 {
			compatible = "mediatek,mt8189-smi-sub-common", "mediatek,smi-common",
				     "syscon", "mediatek,smi-sub-common";
			reg = <0 0x1a00d000 0 0x1000>;
			clocks = <&camsys_main_clk CLK_CAM_M_CAM2MM_GALS>,
				 <&camsys_main_clk CLK_CAM_M_CAM2MM_GALS>;
			clock-names = "apb", "smi";
			mediatek,common-id = <6>;
			mediatek,smi = <&smi_disp_common>;
			power-domains = <&scpsys MT8189_POWER_DOMAIN_CAM_MAIN>;
		};

		smi_larb16: smi-larb16@1a00f000 {
			compatible = "mediatek,mt8189-smi-larb", "mediatek,smi-larb";
			reg = <0 0x1a00f000 0 0x1000>;
			clocks = <&camsys_rawa_clk CLK_CAM_RA_CAMSYS_RAWA_LARBX>,
				 <&camsys_rawa_clk CLK_CAM_RA_CAMSYS_RAWA_LARBX>;
			clock-names = "apb", "smi";
			mediatek,larb-id = <SMI_L16_ID>;
			mediatek,smi = <&smi_cam_3x1_sub_comm>;
			power-domains = <&scpsys MT8189_POWER_DOMAIN_CAM_SUBA>;
		};

		smi_larb17: smi-larb17@1a010000 {
			compatible = "mediatek,mt8189-smi-larb", "mediatek,smi-larb";
			reg = <0 0x1a010000 0 0x1000>;
			clocks = <&camsys_rawb_clk CLK_CAM_RB_CAMSYS_RAWB_LARBX>,
				 <&camsys_rawb_clk CLK_CAM_RB_CAMSYS_RAWB_LARBX>;
			clock-names = "apb", "smi";
			mediatek,larb-id = <SMI_L17_ID>;
			mediatek,smi = <&smi_cam_4x1_sub_comm>;
			power-domains = <&scpsys MT8189_POWER_DOMAIN_CAM_SUBB>;
		};

		camsys_rawa_clk: syscon@1a04f000 {
			compatible = "mediatek,mt8189-camsys_rawa", "syscon";
			reg = <0 0x1a04f000 0 0x1000>;
			#clock-cells = <1>;
		};

		camsys_rawb_clk: syscon@1a06f000 {
			compatible = "mediatek,mt8189-camsys_rawb", "syscon";
			reg = <0 0x1a06f000 0 0x1000>;
			#clock-cells = <1>;
		};

		ipesys_clk: syscon@1b000000 {
			compatible = "mediatek,mt8189-ipesys", "syscon";
			reg = <0 0x1b000000 0 0x1000>;
			#clock-cells = <1>;
		};

		smi_ipe_2x1_sub_comm: smi-ipe-2x1-sub-comm@1b00e000 {
			compatible = "mediatek,mt8189-smi-sub-common", "mediatek,smi-common",
				     "syscon", "mediatek,smi-sub-common";
			reg = <0 0x1b00e000 0 0x1000>;
			clocks = <&ipesys_clk CLK_IPE_SMI_SUBCOM>,
				 <&ipesys_clk CLK_IPESYS_GALS>;
			clock-names = "apb", "smi";
			mediatek,common-id = <8>;
			mediatek,smi = <&smi_disp_common>;
			power-domains = <&scpsys MT8189_POWER_DOMAIN_ISP_IPE>;
		};

		smi_larb20: smi-larb20@1b00f000 {
			compatible = "mediatek,mt8189-smi-larb", "mediatek,smi-larb";
			reg = <0 0x1b00f000 0 0x1000>;
			clocks = <&ipesys_clk CLK_IPE_LARB20>,
				 <&ipesys_clk CLK_IPE_LARB20>;
			clock-names = "apb", "smi";
			mediatek,larb-id = <SMI_L20_ID>;
			mediatek,smi = <&smi_ipe_2x1_sub_comm>;
			power-domains = <&scpsys MT8189_POWER_DOMAIN_ISP_IPE>;
		};

		smi_larb19: smi-larb19@1b10f000 {
			compatible = "mediatek,mt8189-smi-larb", "mediatek,smi-larb";
			reg = <0 0x1b10f000 0 0x1000>;
			clocks = <&ipesys_clk CLK_IPE_LARB19>,
				 <&ipesys_clk CLK_IPE_LARB19>;
			clock-names = "apb", "smi";
			mediatek,larb-id = <SMI_L19_ID>;
			mediatek,smi = <&smi_ipe_2x1_sub_comm>;
			power-domains = <&scpsys MT8189_POWER_DOMAIN_ISP_IPE>;
		};

		vlpcfg_ao_reg_clk: syscon@1c000000 {
			compatible = "mediatek,mt8189-vlp_ao_ckgen", "syscon";
			reg = <0 0x1c000000 0 0x1000>;
			#clock-cells = <1>;
		};

		scpsys: power-controller@1c001000 {
			compatible = "mediatek,mt8189-scpsys", "syscon";
			reg = <0 0x1c001000 0 0x1000>;
			#power-domain-cells = <1>;
			infra-infracfg-ao-reg-bus = <&infracfg_ao_clk>;
			emicfg-ao-mem = <&emicfg_ao_mem_clk>;
			vlpcfg-reg-bus = <&vlpcfg_reg_bus_clk>;
			clocks = /* MFG */
				<&topckgen_clk CLK_TOP_MFG_REF_SEL>,
				/* AUDIO */
				<&topckgen_clk CLK_TOP_AUD_INTBUS_SEL>,
				/* VEN */
				<&topckgen_clk CLK_TOP_VENC_SEL>,
				/* VDEC */
				<&topckgen_clk CLK_TOP_VDEC_SEL>,
				/* IPE */
				<&topckgen_clk CLK_TOP_IPE_SEL>,
				/* CAM_MAIN */
				<&topckgen_clk CLK_TOP_CAM_SEL>,
				/* IMG1 */
				<&topckgen_clk CLK_TOP_IMG1_SEL>,
				/* DISP */
				<&topckgen_clk CLK_TOP_DISP0_SEL>,
				/* MDP0 */
				<&topckgen_clk CLK_TOP_MDP0_SEL>,
				/* MM_INFRA */
				<&topckgen_clk CLK_TOP_MMINFRA_SEL>,
				/* VADSP */
				<&vlp_cksys_clk CLK_VLP_CK_VADSP_SEL>,
				/* IPE */
				<&ipesys_clk CLK_IPE_LARB19>,
				<&ipesys_clk CLK_IPE_LARB20>,
				<&ipesys_clk CLK_IPE_SMI_SUBCOM>,
				<&ipesys_clk CLK_IPESYS_GALS>,
				/* CAMSYS */
				/* cam_main*/
				<&camsys_main_clk CLK_CAM_M_LARB13>,
				<&camsys_main_clk CLK_CAM_M_LARB14>,
				<&camsys_main_clk CLK_CAM_M_CAM2MM_GALS>,
				/* cam_suba */
				<&camsys_rawa_clk CLK_CAM_RA_CAMSYS_RAWA_LARBX>,
				/* cam_subb */
				<&camsys_rawb_clk CLK_CAM_RB_CAMSYS_RAWB_LARBX>,
				/* IMG1 */
				<&imgsys1_clk CLK_IMGSYS1_LARB9>,
				<&imgsys1_clk CLK_IMGSYS1_LARB11>,
				<&imgsys1_clk CLK_IMGSYS1_GALS>,
				/* IMG2 */
				<&imgsys2_clk CLK_IMGSYS2_LARB9>,
				<&imgsys2_clk CLK_IMGSYS2_LARB11>,
				<&imgsys2_clk CLK_IMGSYS2_GALS>,
				/* MMINFRA */
				<&mminfra_config_clk CLK_MMINFRA_SMI>,
				/* DISP */
				<&dispsys_config_clk CLK_MM_SMI_LARB>,
				/* VDEC */
				<&vdec_core_clk CLK_VDEC_CORE_LARB_CKEN>,
				/* VENC */
				<&venc_gcon_clk CLK_VEN1_CKE0_LARB>,
				/* MDP0 */
				<&mdpsys_config_clk CLK_MDP_SMI0>;
			clock-names = "mfg1", "audio", "venc", "vdec", "ipe", "cam",
				"img1", "disp",
				"mdp", "mm_infra", "vadsp",
				"ipe-0", "ipe-1", "ipe-2", "ipe-3",
				"cam_main-0", "cam_main-1", "cam_main-2",
				"cam_suba-0", "cam-subb-0",
				"img1-0", "img1-1", "img1-2",
				"img2-0", "img2-1", "img2-2",
				"mm_infra-0",
				"disp-0",
				"vdec-0", "venc-0",
				"mdp0-0";
			mfg0-supply = <&mt6359_vproc1_buck_reg>;
			mfg1-supply = <&mt6359_vsram_proc1_ldo_reg>;
		};

		vlpcfg_reg_bus_clk: syscon@1c00c000 {
			compatible = "mediatek,mt8189-vlpcfg_reg_bus", "syscon";
			reg = <0 0x1c00c000 0 0x1000>;
			#clock-cells = <1>;
		};

		dvfsrc_top_clk: syscon@1c00f000 {
			compatible = "mediatek,mt8189-dvfsrc_top", "syscon";
			reg = <0 0x1c00f000 0 0x1000>;
			#clock-cells = <1>;
		};

		vlp_cksys_clk: syscon@1c012000 {
			compatible = "mediatek,mt8189-vlp_ckgen", "syscon";
			reg = <0 0x1c012000 0 0x1000>;
			#clock-cells = <1>;
		};

		scp_iic_clk: syscon@1c80a000 {
			compatible = "mediatek,mt8189-scp_i2c", "syscon";
			reg = <0 0x1c80a000 0 0x1000>;
			#clock-cells = <1>;
		};

		scp_clk: syscon@1cb21000 {
			compatible = "mediatek,mt8189-scp", "syscon";
			reg = <0 0x1cb21000 0 0x1000>;
			#clock-cells = <1>;
		};

		mminfra_config_clk: syscon@1e800000 {
			compatible = "mediatek,mt8189-mm_infra", "syscon";
			reg = <0 0x1e800000 0 0x1000>;
			#clock-cells = <1>;
		};

		mminfra {
			compatible = "mediatek,mt8189-mminfra";
			clocks = <&mminfra_config_clk CLK_MMINFRA_GCE_D>,
				 <&mminfra_config_clk CLK_MMINFRA_GCE_M>,
				 <&mminfra_config_clk CLK_MMINFRA_GCE_26M>;
			clock-names = "gce_d", "gce_m", "gce_26m";
			power-domains = <&scpsys MT8189_POWER_DOMAIN_MM_INFRA>;
			mediatek,mminfra = <&mminfra_config_clk>;
		};

		smi_disp_common: smi-disp-comm@1e801000 {
			compatible = "mediatek,mt8189-smi-common",
				     "mediatek,smi-common", "syscon";
			reg = <0 0x1e801000 0 0x1000>;
			clocks = <&mminfra_config_clk CLK_MMINFRA_SMI>,
				 <&mminfra_config_clk CLK_MMINFRA_SMI>;
			clock-names = "apb", "smi";
			mediatek,common-id = <0>;
			power-domains = <&scpsys MT8189_POWER_DOMAIN_MM_INFRA>;
		};

		mm_iommu: iommu@1e802000 {
			compatible = "mediatek,mt8189-iommu-mm";
			reg = <0 0x1e802000 0 0x5000>;
			interrupts = <GIC_SPI 278 IRQ_TYPE_LEVEL_HIGH 0>,
				     <GIC_SPI 279 IRQ_TYPE_LEVEL_HIGH 0>,
				     <GIC_SPI 280 IRQ_TYPE_LEVEL_HIGH 0>,
				     <GIC_SPI 281 IRQ_TYPE_LEVEL_HIGH 0>,
				     <GIC_SPI 282 IRQ_TYPE_LEVEL_HIGH 0>;
			clocks = <&mminfra_config_clk CLK_MMINFRA_SMI>;
			clock-names = "bclk";
			#iommu-cells = <1>;
			mediatek,larbs = <&smi_larb0 &smi_larb1 &smi_larb2 &smi_larb4 &smi_larb7
					  &smi_larb9 &smi_larb11 &smi_larb13 &smi_larb14
					  &smi_larb16 &smi_larb17 &smi_larb19 &smi_larb20>;
			power-domains = <&scpsys MT8189_POWER_DOMAIN_MM_INFRA>;
		};

		disp_ssc0_smi_2x1_sub_comm: disp-ssc0-smi-2x1-sub-comm@1e807000 {
			compatible = "mediatek,mt8189-smi-common", "mediatek,smi-common",
				     "syscon", "mediatek,smi-sub-common";
			reg = <0 0x1e807000 0 0x1000>;
			clocks = <&mminfra_config_clk CLK_MMINFRA_SMI>,
				 <&mminfra_config_clk CLK_MMINFRA_SMI>;
			clock-names = "apb", "smi";
			mediatek,common-id = <1>;
			power-domains = <&scpsys MT8189_POWER_DOMAIN_MM_INFRA>;
		};

		disp_ssc1_smi_2x1_sub_comm: disp-ssc1-smi-2x1-sub-comm@1e808000 {
			compatible = "mediatek,mt8189-smi-common", "mediatek,smi-common",
				     "syscon", "mediatek,smi-sub-common";
			reg = <0 0x1e808000 0 0x1000>;
			clocks = <&mminfra_config_clk CLK_MMINFRA_SMI>,
				 <&mminfra_config_clk CLK_MMINFRA_SMI>;
			clock-names = "apb", "smi";
			mediatek,common-id = <2>;
			power-domains = <&scpsys MT8189_POWER_DOMAIN_MM_INFRA>;
		};

		mminfra_smi_3x1_sub_comm: mminfra-smi-3x1-sub-comm@1e809000 {
			compatible = "mediatek,mt8189-smi-sub-common", "mediatek,smi-common",
				     "syscon", "mediatek,smi-sub-common";
			reg = <0 0x1e809000 0 0x1000>;
			clocks = <&mminfra_config_clk CLK_MMINFRA_SMI>,
				 <&mminfra_config_clk CLK_MMINFRA_SMI>;
			clock-names = "apb", "smi";
			mediatek,smi = <&smi_disp_common>;
			mediatek,common-id = <3>;
			power-domains = <&scpsys MT8189_POWER_DOMAIN_MM_INFRA>;
		};

		mminfra_smi_2x1_sub_comm: mminfra-smi-2x1-sub-comm@1e80a000 {
			compatible = "mediatek,mt8189-smi-sub-common", "mediatek,smi-common",
				     "syscon", "mediatek,smi-sub-common";
			reg = <0 0x1e80a000 0 0x1000>;
			clocks = <&mminfra_config_clk CLK_MMINFRA_SMI>,
				 <&mminfra_config_clk CLK_MMINFRA_SMI>;
			clock-names = "apb", "smi";
			mediatek,smi = <&smi_disp_common>;
			mediatek,common-id = <4>;
			power-domains = <&scpsys MT8189_POWER_DOMAIN_MM_INFRA>;
		};

		gce_d_clk: syscon@1e980000 {
			compatible = "mediatek,mt8189-gce_d", "syscon";
			reg = <0 0x1e980000 0 0x1000>;
			#clock-cells = <1>;
		};

		gce_m_clk: syscon@1e990000 {
			compatible = "mediatek,mt8189-gce_m", "syscon";
			reg = <0 0x1e990000 0 0x1000>;
			#clock-cells = <1>;
		};

		mdpsys_config_clk: syscon@1f000000 {
			compatible = "mediatek,mt8189-mdpsys", "syscon";
			reg = <0 0x1f000000 0 0x1000>;
			#clock-cells = <1>;
		};

		smi_larb2: smi-larb2@1f002000 {
			compatible = "mediatek,mt8189-smi-larb", "mediatek,smi-larb";
			reg = <0 0x1f002000 0 0x1000>;
			clocks = <&mdpsys_config_clk CLK_MDP_SMI0>,
				 <&mdpsys_config_clk CLK_MDP_SMI0>;
			clock-names = "apb", "smi";
			mediatek,larb-id = <SMI_L2_ID>;
			mediatek,smi = <&smi_disp_common>;
			power-domains = <&scpsys MT8189_POWER_DOMAIN_MDP0>;
		};

		eint: apirq@11ce0000 {
			compatible = "mediatek,mtk-eint";
			reg = <0 0x11ce0000 0 0x1000>,
			      <0 0x11de0000 0 0x1000>,
			      <0 0x11e60000 0 0x1000>,
			      <0 0x1c01e000 0 0x1000>,
			      <0 0x11f00000 0 0x1000>;
			reg-name = "eint-e", "eint-s", "eint-w", "eint-c", "eint-n";
			interrupts = <GIC_SPI 239 IRQ_TYPE_LEVEL_HIGH 0>;
			mediatek,instance-num = <5>;
			mediatek,total-pin-number = <210>;
			mediatek,pins = <0 0 0 1>,<1 0 1 1>,<2 0 2 1>,<3 0 3 1>,
					<4 0 4 1>,<5 0 5 1>,<6 0 6 1>,<7 0 7 1>,
					<8 0 8 1>,<9 0 9 1>,<10 0 10 1>,<11 0 11 1>,
					<12 1 0 1>,<13 1 1 1>,<14 1 2 1>,<15 1 3 1>,
					<16 1 4 1>,<17 1 5 1>,<18 0 12 1>,<19 0 13 1>,
					<20 0 14 1>,<21 0 15 1>,<22 0 16 1>,<23 0 17 1>,
					<24 0 18 1>,<25 2 0 1>,<26 2 1 1>,<27 1 6 1>,
					<28 1 7 1>,<29 2 2 1>,<30 1 8 1>,<31 1 9 1>,
					<32 1 10 1>,<33 1 11 1>,<34 1 12 1>,<35 1 13 1>,
					<36 1 14 1>,<37 1 15 1>,<38 1 16 1>,<39 1 17 1>,
					<40 1 18 1>,<41 1 19 1>,<42 1 20 1>,<43 1 21 1>,
					<44 0 19 1>,<45 0 20 1>,<46 0 21 1>,<47 0 22 1>,
					<48 2 3 1>,<49 2 4 1>,<50 2 5 1>,<51 0 23 1>,
					<52 0 24 1>,<53 0 25 1>,<54 0 26 1>,<55 2 6 1>,
					<56 2 7 1>,<57 1 22 1>,<58 1 23 1>,<59 1 24 1>,
					<60 1 25 1>,<61 1 26 1>,<62 1 27 1>,<63 1 28 1>,
					<64 1 29 1>,<65 0 27 1>,<66 0 28 1>,<67 0 29 1>,
					<68 0 30 1>,<69 1 30 1>,<70 1 31 1>,<71 1 32 1>,
					<72 1 33 1>,<73 1 34 1>,<74 1 35 1>,<75 1 36 1>,
					<76 1 37 1>,<77 0 31 1>,<78 0 32 1>,<79 0 33 1>,
					<80 0 34 1>,<81 1 38 1>,<82 1 39 1>,<83 1 40 1>,
					<84 0 35 1>,<85 0 36 1>,<86 0 37 1>,<87 0 38 1>,
					<88 2 8 1>,<89 2 9 1>,<90 2 10 1>,<91 2 11 1>,
					<92 2 12 1>,<93 2 13 1>,<94 2 14 1>,<95 2 15 1>,
					<96 2 16 1>,<97 2 17 1>,<98 2 18 1>,<99 2 19 1>,
					<100 2 20 1>,<101 2 21 1>,<102 2 22 1>,<103 0 39 1>,
					<104 0 40 1>,<105 0 41 1>,<106 0 42 1>,<107 0 43 1>,
					<108 0 44 1>,<109 0 45 1>,<110 0 46 1>,<111 0 47 1>,
					<112 0 48 0>,<113 0 49 1>,<114 0 50 0>,<115 1 41 1>,
					<116 1 42 1>,<117 1 43 1>,<118 1 44 1>,<119 1 45 1>,
					<120 1 46 1>,<121 1 47 1>,<122 1 48 1>,<123 1 49 1>,
					<124 1 50 1>,<125 1 51 1>,<126 1 52 1>,<127 1 53 1>,
					<128 1 54 1>,<129 1 55 1>,<130 1 56 1>,<131 1 57 1>,
					<132 1 58 1>,<133 1 59 1>,<134 1 60 1>,<135 1 61 1>,
					<136 1 62 1>,<137 1 63 1>,<138 1 64 1>,<139 1 65 1>,
					<140 1 66 1>,<141 1 67 1>,<142 1 68 1>,<143 1 69 1>,
					<144 1 70 1>,<145 1 71 1>,<146 1 72 1>,<147 1 73 1>,
					<148 1 74 1>,<149 1 75 1>,<150 1 76 1>,<151 1 77 1>,
					<152 1 78 1>,<153 1 79 1>,<154 1 80 1>,<155 1 81 1>,
					<156 2 23 1>,<157 2 24 1>,<158 2 25 1>,<159 4 0 1>,
					<160 2 26 1>,<161 2 27 1>,<162 2 28 1>,<163 4 1 1>,
					<164 2 29 1>,<165 2 30 1>,<166 4 2 1>,<167 2 31 0>,
					<168 1 82 1>,<169 1 83 1>,<170 1 84 1>,<171 1 85 0>,
					<172 1 86 1>,<173 1 87 0>,<174 4 3 1>,<175 4 4 1>,
					<176 4 5 1>,<177 4 6 1>,<178 4 7 1>,<179 4 8 1>,
					<180 2 32 1>,<181 2 33 0>,<182 3 0 1>,<183 3 1 1>,
					<184 3 2 1>,<185 3 3 1>,<186 3 4 1>,<187 3 5 1>,
					<188 3 6 1>,<189 3 7 1>,<190 3 8 1>,<191 3 9 1>,
					<192 3 10 1>,<193 3 11 1>,<194 3 12 1>,<195 3 13 1>,
					<196 3 14 1>,<197 3 15 1>,<198 3 16 1>,<199 3 17 1>,
					<200 3 18 1>,<201 3 19 1>,<202 3 20 1>,<203 3 21 1>,
					<204 3 22 1>,<205 3 23 1>,<206 3 24 1>,<207 3 25 1>,
					<208 3 26 1>,<209 3 27 1>;
		};

		disp_pwm0: disp-pwm0@1100e000 {
			compatible = "mediatek,mt8183-disp-pwm";
			reg = <0 0x1100e000 0 0x1000>;
			interrupts = <GIC_SPI 471 IRQ_TYPE_LEVEL_HIGH 0>;
			#pwm-cells = <2>;
			clocks = <&pericfg_ao_clk  CLK_PERAO_DISP_PWM0>,
				 <&topckgen_clk CLK_TOP_DISP_PWM_SEL>,
				 <&topckgen_clk CLK_TOP_OSC_D4>;
			clock-names = "main", "mm", "pwm_src";
		};

		disp_pwm1: disp-pwm1@1100f000 {
			compatible = "mediatek,mt8183-disp-pwm";
			reg = <0 0x1100f000 0 0x1000>;
			interrupts = <GIC_SPI 470 IRQ_TYPE_LEVEL_HIGH 0>;
			#pwm-cells = <2>;
			clocks = <&pericfg_ao_clk  CLK_PERAO_DISP_PWM1>,
				 <&topckgen_clk CLK_TOP_DISP_PWM_SEL>,
				 <&topckgen_clk CLK_TOP_OSC_D4>;
			clock-names = "main", "mm", "pwm_src";
		};

		dsi0: dsi@14016000 {
			compatible = "mediatek,mt8188-dsi";
			reg = <0 0x14016000 0 0x1000>, <0 0x14000000 0 0x1000>;
			interrupts = <GIC_SPI 326 IRQ_TYPE_LEVEL_HIGH 0>;
			power-domains = <&scpsys MT8189_POWER_DOMAIN_DISP>;
			phys = <&mipi_tx_config0>;
			phy-names = "dphy";
			clocks = <&dispsys_config_clk CLK_MMSYS_0_DISP_DSI0>,
				 <&dispsys_config_clk CLK_MMSYS_1_DISP_DSI0>,
				 <&mipi_tx_config0>;
			clock-names = "engine", "digital", "hs";
		};

		mipi_tx_config0: mipi-tx-config0@11b40000 {
			compatible = "mediatek,mt8183-mipi-tx";
			reg = <0 0x11b40000 0 0x1000>;
			clocks = <&clk26m>;
			#clock-cells = <0>;
			#phy-cells = <0>;
			clock-output-names = "mipi_tx0_pll";
			#dispsys-sel-offset = <0x170 0x174>;
			status = "disabled";
		};

		disp_dvo0: disp-dvo0@14017000 {
			compatible = "mediatek,mt8189-edp-dvo";
			status = "disabled";
			reg = <0 0x14017000 0 0x1000>;
			interrupts = <GIC_SPI 325 IRQ_TYPE_LEVEL_HIGH 0>;
			clocks = <&dispsys_config_clk CLK_MMSYS_1_DISP_DVO>,
						<&topckgen_clk CLK_TOP_EDP_SEL>,
						<&apmixedsys_clk CLK_APMIXED_TVDPLL2>,
						<&topckgen_clk CLK_TOP_TCK_26M_MX9>,
						<&dispsys_config_clk CLK_MMSYS_0_DISP_DVO>,
						<&topckgen_clk CLK_TOP_TVDPLL2_D2>,
						<&topckgen_clk CLK_TOP_TVDPLL2_D4>,
						<&topckgen_clk CLK_TOP_TVDPLL2_D8>,
						<&topckgen_clk CLK_TOP_TVDPLL2_D16>;
			clock-names = "engine",
						"pixel",
						"pll",
						"dvo_clk",
						"hf_fdvo_clk",
						"TVDPLL2_D2",
						"TVDPLL2_D4",
						"TVDPLL2_D8",
						"TVDPLL2_D16";
		};

		edp_tx: edp-tx@11b70000 {
			status = "disabled";
			compatible = "mediatek,mt8189-edp-tx";
			reg = <0 0x11b70000 0 0x14000>,
				<0 0x11e10000 0 0x1500>;
			max-lanes = <4>;
			max-linkrate-mhz = <5400>;
			power-domains = <&scpsys MT8189_POWER_DOMAIN_EDP_TX_DORMANT>;
			interrupts = <GIC_SPI 380 IRQ_TYPE_LEVEL_HIGH 0>;
		};

		disp_dvo1: disp-dvo1@14018000 {
			compatible = "mediatek,mt8189-dp-dvo";
			status = "disabled";
			reg = <0 0x14018000 0 0x1000>;
			interrupts = <GIC_SPI 357 IRQ_TYPE_LEVEL_HIGH 0>;
			clocks = <&dispsys_config_clk CLK_MM_DP_INTF>,
				 <&topckgen_clk CLK_TOP_DP_SEL>,
				 <&apmixedsys_clk CLK_APMIXED_TVDPLL1>,
				 <&topckgen_clk CLK_TOP_TCK_26M_MX9>,
				 <&topckgen_clk CLK_TOP_DP>,
				 <&topckgen_clk CLK_TOP_TVDPLL1_D2>,
				 <&topckgen_clk CLK_TOP_TVDPLL1_D4>,
				 <&topckgen_clk CLK_TOP_TVDPLL1_D8>,
				 <&topckgen_clk CLK_TOP_TVDPLL1_D16>;

			clock-names = "engine",
				      "pixel",
				      "pll",
				      "dvo_clk",
				      "hf_fdvo_clk",
				      "TVDPLL2_D2",
				      "TVDPLL2_D4",
				      "TVDPLL2_D8",
				      "TVDPLL2_D16";
		};

		dp_tx: dp-tx@11b60000 {
			status = "disabled";
			compatible = "mediatek,mt8189-dp-tx";
			#sound-dai-cells = <0>;
			power-domains = <&scpsys MT8189_POWER_DOMAIN_DP_TX>,
							<&scpsys MT8189_POWER_DOMAIN_SSUSB>;
			power-domain-names = "pd_dp_tx",
							"pd_dp_phy";
			reg = <0 0x11b60000 0 0x5000>,
			      <0 0x11c10000 0 0x1500>,
			      <0 0x10011018 0 0x4>;
			interrupts = <GIC_SPI 199 IRQ_TYPE_LEVEL_HIGH 0>;
			clocks = <&topckgen_clk CLK_TOP_DP_SEL>,
				<&topckgen_clk CLK_TOP_TCK_26M_MX9>;
			clock-names = "mux_dp",
					"ck_26m";
		};

		lvds_tx: lvds-tx@11b30000 {
			compatible = "mediatek,mt8189-lvds-tx";
			reg = <0 0x11b30000 0 0x308>,
				<0 0x11b40000 0 0x1000>;
			#phy-cells = <0>;
			status = "disabled";
		};

		disp_dvo2: disp-dvo2@14019000 {
			compatible = "mediatek,mt8189-lvds-dvo";
			reg = <0 0x14019000 0 0x1000>;
			interrupts = <GIC_SPI 328 IRQ_TYPE_LEVEL_LOW 0>;
			power-domains = <&scpsys MT8189_POWER_DOMAIN_DISP>;
			clocks = <&dispsys_config_clk CLK_MMSYS_1_DPI0>,
					 <&topckgen_clk CLK_TOP_VDSTX_DG_CTS_SEL>,
					 <&topckgen_clk CLK_TOP_LVDSTX_DG_CTS>,
					 <&topckgen_clk CLK_TOP_PLL_DPIX_SEL>,
					 <&topckgen_clk CLK_TOP_PLL_DPIX>,
					 <&dispsys_config_clk CLK_MM_DPI0>,
					 <&dispsys_config_clk CLK_MMSYS_1_LVDS_ENCODER>,
					 <&dispsys_config_clk CLK_MMSYS_1_LVDS_ENCODER_CTS>;
			clock-names = "engine", "pixel", "pll", "dvo_clk", "dvo_pa",
							"dvo_sysclk", "sysclk", "sysclk_cts";
			status = "disabled";
		};

		lvds: lvds@1401e200 {
			compatible = "mediatek,mt8189-lvds";/*lvds_encoder*/
			reg = <0 0x1401e200 0 0x74>;
			phys = <&lvds_tx>;
			phy-names = "lvds";
			status = "disabled";
		};

		watchdog: watchdog@1c00a000 {
			compatible = "mediatek,mt6589-wdt";
			reg = <0 0x1c00a000 0 0x100>;
			mediatek,disable-extrst;
			#reset-cells = <1>;
		};

		systimer: timer@1cc10000 {
			compatible = "mediatek,mt6765-timer";
			reg = <0 0x1cc10000 0 0x1000>;
			interrupts = <GIC_SPI 249 IRQ_TYPE_LEVEL_HIGH 0>;
			clocks = <&clk13m>;
		};

		gce0: mailbox@1e980000 {
			compatible = "mediatek,mt8189-gce";
			reg = <0 0x1e980000 0 0x4000>;
			interrupts = <GIC_SPI 290 IRQ_TYPE_LEVEL_HIGH 0>;
			#mbox-cells = <2>;
			power-domains = <&scpsys MT8189_POWER_DOMAIN_MM_INFRA>;
			clocks = <&mminfra_config_clk CLK_MMINFRA_GCE_D>,
				<&mminfra_config_clk CLK_MMINFRA_GCE_26M>;
			clock-names = "gce0","gce-timer";
		};

		gce1: mailbox@1e990000 {
			compatible = "mediatek,mt8189-gce";
			reg = <0 0x1e990000 0 0x4000>;
			interrupts = <GIC_SPI 286 IRQ_TYPE_LEVEL_HIGH 0>;
			#mbox-cells = <2>;
			power-domains = <&scpsys MT8189_POWER_DOMAIN_MM_INFRA>;
			clocks = <&mminfra_config_clk CLK_MMINFRA_GCE_M>,
				<&mminfra_config_clk CLK_MMINFRA_GCE_26M>;
			clock-names = "gce1","gce-timer";
		};

		i2c0: i2c@11c20000 {
			compatible = "mediatek,mt8188-i2c";
			reg = <0 0x11c20000 0 0x1000>,
				<0 0x11300200 0 0x80>;
			interrupts = <GIC_SPI 274 IRQ_TYPE_LEVEL_HIGH 0>;
			clocks = <&imp_iic_wrap_e_clk CLK_IMPE_I2C0>,
				<&pericfg_ao_clk CLK_PERAO_DMA_B>;
			clock-names = "main", "dma";
			clock-div = <1>;
			#address-cells = <1>;
			#size-cells = <0>;
			status = "disabled";
		};

		i2c1: i2c@11c21000 {
			compatible = "mediatek,mt8188-i2c";
			reg = <0 0x11c21000 0 0x1000>,
				<0 0x11300300 0 0x80>;
			interrupts = <GIC_SPI 275 IRQ_TYPE_LEVEL_HIGH 0>;
			clocks = <&imp_iic_wrap_e_clk CLK_IMPE_I2C1>,
				<&pericfg_ao_clk CLK_PERAO_DMA_B>;
			clock-names = "main", "dma";
			clock-div = <1>;
			#address-cells = <1>;
			#size-cells = <0>;
			status = "disabled";
		};

		i2c2: i2c@11b20000 {
			compatible = "mediatek,mt8188-i2c";
			reg = <0 0x11b20000 0 0x1000>,
				<0 0x11300400 0 0x80>;
			interrupts = <GIC_SPI 276 IRQ_TYPE_LEVEL_HIGH 0>;
			clocks = <&imp_iic_wrap_ws_clk CLK_IMPWS_I2C2>,
				<&pericfg_ao_clk CLK_PERAO_DMA_B>;
			clock-names = "main", "dma";
			clock-div = <1>;
			#address-cells = <1>;
			#size-cells = <0>;
			status = "disabled";
		};

		i2c3: i2c@11d70000 {
			compatible = "mediatek,mt8188-i2c";
			#address-cells = <1>;
			#size-cells = <0>;
			reg = <0 0x11d70000 0 0x1000>,
				<0 0x11300500 0 0x80>;
			interrupts = <GIC_SPI 277 IRQ_TYPE_LEVEL_HIGH 0>;
			clocks = <&imp_iic_wrap_s_clk CLK_IMPS_I2C3>,
				<&pericfg_ao_clk CLK_PERAO_DMA_B>;
			clock-names = "main", "dma";
			clock-div = <1>;
			status = "disabled";
		};

		i2c4: i2c@11d71000 {
			compatible = "mediatek,mt8188-i2c";
			reg = <0 0x11d71000 0 0x1000>,
				<0 0x11300600 0 0x80>;
			interrupts = <GIC_SPI 208 IRQ_TYPE_LEVEL_HIGH 0>;
			clocks = <&imp_iic_wrap_s_clk CLK_IMPS_I2C4>,
				<&pericfg_ao_clk CLK_PERAO_DMA_B>;
			clock-names = "main", "dma";
			clock-div = <1>;
			#address-cells = <1>;
			#size-cells = <0>;
			status = "disabled";
		};

		i2c5: i2c@11d72000 {
			compatible = "mediatek,mt8188-i2c";
			#address-cells = <1>;
			#size-cells = <0>;
			reg = <0 0x11d72000 0 0x1000>,
				<0 0x11300700 0 0x80>;
			interrupts = <GIC_SPI 209 IRQ_TYPE_LEVEL_HIGH 0>;
			clocks = <&imp_iic_wrap_s_clk CLK_IMPS_I2C5>,
				<&pericfg_ao_clk CLK_PERAO_DMA_B>;
			clock-names = "main", "dma";
			clock-div = <1>;
			status = "disabled";
		};

		i2c6: i2c@11d73000 {
			compatible = "mediatek,mt8188-i2c";
			#address-cells = <1>;
			#size-cells = <0>;
			reg = <0 0x11d73000 0 0x1000>,
				<0 0x11300800 0 0x80>;
			interrupts = <GIC_SPI 210 IRQ_TYPE_LEVEL_HIGH 0>;
			clocks = <&imp_iic_wrap_s_clk CLK_IMPS_I2C6>,
				<&pericfg_ao_clk CLK_PERAO_DMA_B>;
			clock-names = "main", "dma";
			clock-div = <1>;
			status = "disabled";
		};

		i2c7: i2c@11f30000 {
			compatible = "mediatek,mt8188-i2c";
			reg = <0 0x11f30000 0 0x1000>,
				<0 0x11300900 0 0x80>;
			interrupts = <GIC_SPI 211 IRQ_TYPE_LEVEL_HIGH 0>;
			clocks = <&imp_iic_wrap_en_clk CLK_IMPEN_I2C7>,
				<&pericfg_ao_clk CLK_PERAO_DMA_B>;
			clock-names = "main", "dma";
			clock-div = <1>;
			#address-cells = <1>;
			#size-cells = <0>;
			status = "disabled";
		};

		i2c8: i2c@11f31000 {
			compatible = "mediatek,mt8188-i2c";
			reg = <0 0x11f31000 0 0x1000>,
				<0 0x11300a00 0 0x80>;
			interrupts = <GIC_SPI 212 IRQ_TYPE_LEVEL_HIGH 0>;
			clocks = <&imp_iic_wrap_en_clk CLK_IMPEN_I2C8>,
				<&pericfg_ao_clk CLK_PERAO_DMA_B>;
			clock-names = "main", "dma";
			clock-div = <1>;
			#address-cells = <1>;
			#size-cells = <0>;
			status = "disabled";
		};

		eth: ethernet@1101a000 {
			compatible = "mediatek,mt8189-gmac", "snps,dwmac-5.10a";
			reg = <0 0x1101a000 0 0x4000>;
			interrupts = <GIC_SPI 475 IRQ_TYPE_LEVEL_HIGH 0>;
			interrupt-names = "macirq";
			mac-address = [00 55 7b b5 7d f7];
			clock-names = "mac_main",
					"ptp_ref",
					"rmii_internal";
			clocks = <&topckgen_clk CLK_TOP_ETH_250M_SEL>,
				<&topckgen_clk CLK_TOP_ETH_62P4M_PTP_SEL>,
				<&topckgen_clk CLK_TOP_ETH_50M_RMII_SEL>;
			assigned-clocks = <&topckgen_clk CLK_TOP_ETH_250M_SEL>,
				  <&topckgen_clk CLK_TOP_ETH_62P4M_PTP_SEL>,
				  <&topckgen_clk CLK_TOP_ETH_50M_RMII_SEL>;
			assigned-clock-parents = <&topckgen_clk CLK_TOP_ETHPLL_D2>,
						<&topckgen_clk CLK_TOP_ETHPLL_D8>,
						<&topckgen_clk CLK_TOP_ETHPLL_D10>;
			power-domains = <&scpsys MT8189_POWER_DOMAIN_PCIE>;
			mediatek,pericfg = <&pericfg_ao_clk>;
			snps,axi-config = <&stmmac_axi_setup>;
			snps,mtl-rx-config = <&mtl_rx_setup>;
			snps,mtl-tx-config = <&mtl_tx_setup>;
			snps,txpbl = <16>;
			snps,rxpbl = <16>;
			clk-csr = <4>;
			status = "disabled";
		};


		spi0: spi@11010800 {
			compatible = "mediatek,mt8189-spi";
			mediatek,pad-select = <0>;
			reg = <0 0x11010800 0 0x100>;
			interrupts = <GIC_SPI 459 IRQ_TYPE_LEVEL_HIGH 0>;
			clocks = <&topckgen_clk CLK_TOP_UNIVPLL_D6_D2>,
				 <&topckgen_clk CLK_TOP_SPI0_SEL>,
				 <&pericfg_ao_clk CLK_PERAO_SPI0_B>,
				 <&pericfg_ao_clk CLK_PERAO_SPI0_H>;
			clock-names = "parent-clk", "sel-clk", "spi-clk", "hclk";
			#address-cells = <1>;
			#size-cells = <0>;
		};

		spi1: spi@11011800 {
			compatible = "mediatek,mt8189-spi";
			mediatek,pad-select = <0>;
			reg = <0 0x11011800 0 0x100>;
			interrupts = <GIC_SPI 460 IRQ_TYPE_LEVEL_HIGH 0>;
			clocks = <&topckgen_clk CLK_TOP_UNIVPLL_D6_D2>,
				 <&topckgen_clk CLK_TOP_SPI1_SEL>,
				 <&pericfg_ao_clk CLK_PERAO_SPI1_B>,
				 <&pericfg_ao_clk CLK_PERAO_SPI1_H>;
			clock-names = "parent-clk", "sel-clk", "spi-clk", "hclk";
			#address-cells = <1>;
			#size-cells = <0>;
		};

		spi2: spi@11012800 {
			compatible = "mediatek,mt8189-spi";
			mediatek,pad-select = <0>;
			reg = <0 0x11012800 0 0x100>;
			interrupts = <GIC_SPI 461 IRQ_TYPE_LEVEL_HIGH 0>;
			clocks = <&topckgen_clk CLK_TOP_UNIVPLL_D6_D2>,
				 <&topckgen_clk CLK_TOP_SPI2_SEL>,
				 <&pericfg_ao_clk CLK_PERAO_SPI2_B>,
				 <&pericfg_ao_clk CLK_PERAO_SPI2_H>;
			clock-names = "parent-clk", "sel-clk", "spi-clk", "hclk";
			#address-cells = <1>;
			#size-cells = <0>;
		};

		spi3: spi@11013800 {
			compatible = "mediatek,mt8189-spi";
			mediatek,pad-select = <0>;
			reg = <0 0x11013800 0 0x100>;
			interrupts = <GIC_SPI 462 IRQ_TYPE_LEVEL_HIGH 0>;
			clocks = <&topckgen_clk CLK_TOP_UNIVPLL_D6_D2>,
				 <&topckgen_clk CLK_TOP_SPI3_SEL>,
				 <&pericfg_ao_clk CLK_PERAO_SPI3_B>,
				 <&pericfg_ao_clk CLK_PERAO_SPI3_H>;
			clock-names = "parent-clk", "sel-clk", "spi-clk", "hclk";
			#address-cells = <1>;
			#size-cells = <0>;
		};

		spi4: spi@11014800 {
			compatible = "mediatek,mt8189-spi";
			mediatek,pad-select = <0>;
			reg = <0 0x11014800 0 0x100>;
			interrupts = <GIC_SPI 463 IRQ_TYPE_LEVEL_HIGH 0>;
			clocks = <&topckgen_clk CLK_TOP_UNIVPLL_D6_D2>,
				 <&topckgen_clk CLK_TOP_SPI4_SEL>,
				 <&pericfg_ao_clk CLK_PERAO_SPI4_B>,
				 <&pericfg_ao_clk CLK_PERAO_SPI4_H>;
			clock-names = "parent-clk", "sel-clk", "spi-clk", "hclk";
			#address-cells = <1>;
			#size-cells = <0>;
		};

		spi5: spi@11015800 {
			compatible = "mediatek,mt8189-spi";
			mediatek,pad-select = <0>;
			reg = <0 0x11015800 0 0x100>;
			interrupts = <GIC_SPI 464 IRQ_TYPE_LEVEL_HIGH 0>;
			clocks = <&topckgen_clk CLK_TOP_UNIVPLL_D6_D2>,
				 <&topckgen_clk CLK_TOP_SPI5_SEL>,
				 <&pericfg_ao_clk CLK_PERAO_SPI5_B>,
				 <&pericfg_ao_clk CLK_PERAO_SPI5_H>;
			clock-names = "parent-clk", "sel-clk", "spi-clk", "hclk";
			#address-cells = <1>;
			#size-cells = <0>;
		};

		pwrap: pwrap@1cc04000 {
			compatible = "mediatek,mt8189-pwrap";
			reg = <0 0x1cc04000 0 0x1000>;
			reg-names = "pwrap";
			interrupts = <GIC_SPI 496 IRQ_TYPE_LEVEL_HIGH 0>;
			clocks =  <&vlpcfg_reg_bus_clk CLK_VLPCFG_REG_PMIF_SPMI_M_SYS>,
			<&vlpcfg_reg_bus_clk CLK_VLPCFG_REG_PMIF_SPMI_M_TMR>;
			clock-names = "spi", "wrap";
			assigned-clocks = <&vlp_cksys_clk CLK_VLP_CK_PWRAP_ULPOSC_SEL>;
			assigned-clock-parents = <&topckgen_clk CLK_TOP_OSC_D10>;
		};

		efuse: efuse@11f10000 {
			compatible = "mediatek,efuse";
			reg = <0 0x11f10000 0 0x1000>;
			#address-cells = <1>;
			#size-cells = <1>;

			dp_calib_data: dp-calib@1a0 {
				reg = <0x1a0 0xc>;
			};

			lvts_e_data1: data1@1a4 {
				reg = <0x1a4 0x54>;
			};

			lvts_e_data2: data2@1f8 {
				reg = <0x1f8 0x8>;
			};

			socinfo-data1@7a0 {
				reg = <0x7a0 0x4>;
			};

			socinfo-data2@7e0 {
				reg = <0x7e0 0x4>;
			};
		};

		lvts: lvts@10315000 {
			compatible = "mediatek,mt8189-lvts";
			#thermal-sensor-cells = <1>;
			reg = <0 0x10315000 0 0x1000>,
				<0 0x10316000 0 0x1000>;
			interrupts = <GIC_SPI 218 IRQ_TYPE_LEVEL_HIGH 0>,
				<GIC_SPI 219 IRQ_TYPE_LEVEL_HIGH 0>;

			nvmem-cells = <&lvts_e_data1>, <&lvts_e_data2>;
			nvmem-cell-names = "e_data1", "e_data2";
		};

		spmi: spmi@1cc06000 {
			compatible = "mediatek,mt8189-spmi";
			reg = <0 0x1cc06000 0 0x0008ff>,
					<0 0x1cc00000 0 0x000100>;
			reg-names = "pmif", "spmimst";
			clocks = <&vlpcfg_reg_bus_clk CLK_VLPCFG_REG_PMIF_SPMI_P_SYS>,
					<&vlpcfg_reg_bus_clk CLK_VLPCFG_REG_PMIF_SPMI_P_TMR>,
					<&vlp_cksys_clk CLK_VLP_CK_SPMI_P_MST_SEL>;
			clock-names = "pmif_sys_ck", "pmif_tmr_ck", "spmimst_clk_mux";
			#address-cells = <2>;
			#size-cells = <0>;
		};

		auxadc: adc@11019000 {
			compatible = "mediatek,mt8173-auxadc";
			reg = <0 0x11019000 0 0x1000>;
			clocks = <&pericfg_ao_clk CLK_PERAO_AUXADC_26M>;
			clock-names = "main";
			#io-channel-cells = <1>;
			status = "disabled";
		};

		pwm: pwm@11008000 {
			compatible = "mediatek,mt8189-pwm";
			reg = <0 0x11008000 0 0x1000>;
			#pwm-cells = <2>;

			clocks = <&pericfg_ao_clk CLK_PERAO_PWM_H>,
				 <&pericfg_ao_clk CLK_PERAO_PWM_B>,
				 <&pericfg_ao_clk CLK_PERAO_PWM_FB1>,
				 <&pericfg_ao_clk CLK_PERAO_PWM_FB2>,
				 <&pericfg_ao_clk CLK_PERAO_PWM_FB3>;

			clock-names = "top", "main", "pwm1", "pwm2", "pwm3";
		};

		pcie: pcie@112f0000 {
			device_type = "pci";
			compatible = "mediatek,mt8189-pcie",
				     "mediatek,mt8192-pcie";
			reg = <0 0x112f0000 0 0x4000>;
			reg-names = "pcie-mac";
			linux,pci-domain = <0>;
			#address-cells = <3>;
			#size-cells = <2>;
			interrupts = <GIC_SPI 467 IRQ_TYPE_LEVEL_HIGH 0>;
			bus-range = <0x00 0xff>;
			ranges = <0x82000000 0 0x30000000
				  0x0 0x30000000 0 0x04000000>;

			status = "disabled";

			clocks = <&pericfg_ao_clk CLK_PERAO_AXI>,
				 <&pericfg_ao_clk CLK_PERAO_AHB_APB>,
				 <&pericfg_ao_clk CLK_PERAO_TL>,
				 <&pericfg_ao_clk CLK_PERAO_REF>,
				 <&topckgen_clk CLK_TOP_F26M_CK_EN>;

			phys = <&pcieport PHY_TYPE_PCIE>;
			phy-names = "pcie-phy";
			power-domains = <&scpsys MT8189_POWER_DOMAIN_PCIE>;

			#interrupt-cells = <1>;
			interrupt-map-mask = <0 0 0 7>;
			interrupt-map = <0 0 0 1 &pcie_intc 0>,
					<0 0 0 2 &pcie_intc 1>,
					<0 0 0 3 &pcie_intc 2>,
					<0 0 0 4 &pcie_intc 3>;
			pcie_intc: interrupt-controller {
				interrupt-controller;
				#address-cells = <0>;
				#interrupt-cells = <1>;
			};
		};

		pciephy: t-phy@11e50700 {
			compatible = "mediatek,mt8189-tphy",
				     "mediatek,generic-tphy-v2";
			#address-cells = <1>;
			#size-cells = <1>;
			ranges = <0x0 0x0 0x11e50700 0x700>;
			power-domains = <&scpsys MT8189_POWER_DOMAIN_PCIE_PHY>;
			status = "disabled";

			pcieport: pcie-phy@0 {
				reg = <0 0x700>;
				#phy-cells = <1>;
			};
		};

		jpeg_encoder: jpeg-encoder@17030000 {
			compatible = "mediatek,mt8189-jpgenc", "mediatek,mt8188-jpgenc";
			reg = <0 0x17030000 0 0x10000>;
			interrupts = <GIC_SPI 495 IRQ_TYPE_LEVEL_HIGH 0>;
			clocks = <&venc_gcon_clk CLK_VEN1_CKE2_JPGENC>;
			clock-names = "jpgenc";
			power-domains = <&scpsys MT8189_POWER_DOMAIN_VEN0>;
			mediatek,larb = <&smi_larb7>;
			iommus = <&mm_iommu M4U_L7_P5_JPGENC_Y_RDMA>,
				 <&mm_iommu M4U_L7_P6_JPGENC_C_RDMA>,
				 <&mm_iommu M4U_L7_P7_JPGENC_Q_RDMA>,
				 <&mm_iommu M4U_L7_P9_JPGENC_BSDMA>;
		};

		jpeg_decoder: jpeg-decoder@17040000 {
			compatible = "mediatek,mt8189-jpgdec", "mediatek,mt8188-jpgdec";
			reg = <0 0x17040000 0 0x10000>;
			interrupts = <GIC_SPI 381 IRQ_TYPE_LEVEL_HIGH 0>;
			clocks = <&venc_gcon_clk CLK_VEN1_CKE3_JPGDEC>;
			clock-names = "jpgdec";
			power-domains = <&scpsys MT8189_POWER_DOMAIN_VEN0>;
			mediatek,larb = <&smi_larb7>;
			iommus = <&mm_iommu M4U_L7_P15_JPGDEC_WDMA>,
				 <&mm_iommu M4U_L7_P16_JPGDEC_BSDMA>,
				 <&mm_iommu M4U_L7_P17_JPGDEC_HUFF_OFFSET>;
		};

		thermal_zones: thermal-zones {
			soc_max: soc_max {
				polling-delay = <1000>; /* milliseconds */
				polling-delay-passive = <100>; /* milliseconds */
				thermal-sensors = <&lvts 0>;
				sustainable-power = <1200>;

				trips {
					threshold: trip-point@0 {
						temperature = <68000>;
						hysteresis = <2000>;
						type = "passive";
					};

					target: target@1 {
						temperature = <85000>;
						hysteresis = <2000>;
						type = "passive";
					};

					soc_max_crit: soc-max-crit@0 {
						temperature = <115000>;
						hysteresis = <2000>;
						type = "critical";
					};
				};

				cooling-maps {
					map0 {
						trip = <&target>;
						cooling-device =
							<&cpu0 THERMAL_NO_LIMIT THERMAL_NO_LIMIT>,
							<&cpu1 THERMAL_NO_LIMIT THERMAL_NO_LIMIT>,
							<&cpu2 THERMAL_NO_LIMIT THERMAL_NO_LIMIT>,
							<&cpu3 THERMAL_NO_LIMIT THERMAL_NO_LIMIT>,
							<&cpu4 THERMAL_NO_LIMIT THERMAL_NO_LIMIT>,
							<&cpu5 THERMAL_NO_LIMIT THERMAL_NO_LIMIT>;
						contribution = <2345>;
					};

					map1 {
						trip = <&target>;
						cooling-device =
							<&cpu6 THERMAL_NO_LIMIT	THERMAL_NO_LIMIT>,
							<&cpu7 THERMAL_NO_LIMIT	THERMAL_NO_LIMIT>;
						contribution = <1024>;
					};
				};
			};
			cpu-big1 {
				polling-delay = <0>; /* milliseconds */
				polling-delay-passive = <0>; /* milliseconds */
				thermal-sensors = <&lvts 1>;
				trips {
					cpu_big1_crit: cpu-big1-crit {
						temperature = <119000>;
						hysteresis = <2000>;
						type = "critical";
					};
				};
			};
			cpu-big2 {
				polling-delay = <0>; /* milliseconds */
				polling-delay-passive = <0>; /* milliseconds */
				thermal-sensors = <&lvts 2>;
				trips {
					cpu_big2_crit: cpu-big2-crit {
						temperature = <119000>;
						hysteresis = <2000>;
						type = "critical";
					};
				};
			};
			cpu-big3 {
				polling-delay = <0>; /* milliseconds */
				polling-delay-passive = <0>; /* milliseconds */
				thermal-sensors = <&lvts 3>;
				trips {
					cpu_big3_crit: cpu-big3-crit {
						temperature = <119000>;
						hysteresis = <2000>;
						type = "critical";
					};
				};
			};
			cpu-big4 {
				polling-delay = <0>; /* milliseconds */
				polling-delay-passive = <0>; /* milliseconds */
				thermal-sensors = <&lvts 4>;
				trips {
					cpu_big4_crit: cpu-big4-crit {
						temperature = <119000>;
						hysteresis = <2000>;
						type = "critical";
					};
				};
			};
			cpu-little1 {
				polling-delay = <0>; /* milliseconds */
				polling-delay-passive = <0>; /* milliseconds */
				thermal-sensors = <&lvts 5>;
				trips {
					cpu_little1_crit: cpu-little1-crit {
						temperature = <119000>;
						hysteresis = <2000>;
						type = "critical";
					};
				};
			};
			cpu-little2 {
				polling-delay = <0>; /* milliseconds */
				polling-delay-passive = <0>; /* milliseconds */
				thermal-sensors = <&lvts 6>;
				trips {
					cpu_little2_crit: cpu-little2-crit {
						temperature = <119000>;
						hysteresis = <2000>;
						type = "critical";
					};
				};
			};
			cpu-little3 {
				polling-delay = <0>; /* milliseconds */
				polling-delay-passive = <0>; /* milliseconds */
				thermal-sensors = <&lvts 7>;
				trips {
					cpu_little3_crit: cpu-little3-crit {
						temperature = <119000>;
						hysteresis = <2000>;
						type = "critical";
					};
				};
			};
			cpu-little4 {
				polling-delay = <0>; /* milliseconds */
				polling-delay-passive = <0>; /* milliseconds */
				thermal-sensors = <&lvts 8>;
				trips {
					cpu_little4_crit: cpu-little4-crit {
						temperature = <119000>;
						hysteresis = <2000>;
						type = "critical";
					};
				};
			};
			cpu-little5 {
				polling-delay = <0>; /* milliseconds */
				polling-delay-passive = <0>; /* milliseconds */
				thermal-sensors = <&lvts 9>;
				trips {
					cpu_little5_crit: cpu-little5-crit {
						temperature = <119000>;
						hysteresis = <2000>;
						type = "critical";
					};
				};
			};
			cpu-little6 {
				polling-delay = <0>; /* milliseconds */
				polling-delay-passive = <0>; /* milliseconds */
				thermal-sensors = <&lvts 10>;
				trips {
					cpu_little6_crit: cpu-little6-crit {
						temperature = <119000>;
						hysteresis = <2000>;
						type = "critical";
					};
				};
			};
			cpu-little7 {
				polling-delay = <0>; /* milliseconds */
				polling-delay-passive = <0>; /* milliseconds */
				thermal-sensors = <&lvts 11>;
				trips {
					cpu_little7_crit: cpu-little7-crit {
						temperature = <119000>;
						hysteresis = <2000>;
						type = "critical";
					};
				};
			};
			cpu-little8 {
				polling-delay = <0>; /* milliseconds */
				polling-delay-passive = <0>; /* milliseconds */
				thermal-sensors = <&lvts 12>;
				trips {
					cpu_little8_crit: cpu-little8-crit {
						temperature = <119000>;
						hysteresis = <2000>;
						type = "critical";
					};
				};
			};
			soc1 {
				polling-delay = <0>; /* milliseconds */
				polling-delay-passive = <0>; /* milliseconds */
				thermal-sensors = <&lvts 13>;
				trips {
					soc1_crit: soc1-crit {
						temperature = <119000>;
						hysteresis = <2000>;
						type = "critical";
					};
				};
			};
			soc2 {
				polling-delay = <0>; /* milliseconds */
				polling-delay-passive = <0>; /* milliseconds */
				thermal-sensors = <&lvts 14>;
				trips {
					soc2_crit: soc2-crit {
						temperature = <119000>;
						hysteresis = <2000>;
						type = "critical";
					};
				};
			};
			soc3 {
				polling-delay = <0>; /* milliseconds */
				polling-delay-passive = <0>; /* milliseconds */
				thermal-sensors = <&lvts 15>;
				trips {
					soc3_crit: soc3-crit {
						temperature = <119000>;
						hysteresis = <2000>;
						type = "critical";
					};
				};
			};
			apu {
				polling-delay = <0>; /* milliseconds */
				polling-delay-passive = <0>; /* milliseconds */
				thermal-sensors = <&lvts 16>;
				trips {
					apu_crit: apu-crit {
						temperature = <119000>;
						hysteresis = <2000>;
						type = "critical";
					};
				};
			};
			gpu1 {
				polling-delay = <0>; /* milliseconds */
				polling-delay-passive = <0>; /* milliseconds */
				thermal-sensors = <&lvts 17>;
				trips {
					gpu1_crit: gpu1-crit {
						temperature = <119000>;
						hysteresis = <2000>;
						type = "critical";
					};
				};
			};
			gpu2 {
				polling-delay = <0>; /* milliseconds */
				polling-delay-passive = <0>; /* milliseconds */
				thermal-sensors = <&lvts 18>;
				trips {
					gpu2_crit: gpu2-crit {
						temperature = <119000>;
						hysteresis = <2000>;
						type = "critical";
					};
				};
			};
		};

		dispsys_config: dispsys-config@14000000 {
			compatible = "mediatek,mt8189-mmsys", "syscon";
			reg = <0 0x14000000 0 0x1000>;
			#address-cells = <2>;
			#size-cells = <2>;
			#clock-cells = <1>;
			clocks = <&dispsys_config_clk CLK_MM_DISP_MUTEX0>,
				 <&dispsys_config_clk CLK_MM_DIPSYS_CONFIG>;
			power-domains = <&scpsys MT8189_POWER_DOMAIN_DISP>;
			mboxes = <&gce0 0 CMDQ_THR_PRIO_HIGHEST>,
				 <&gce0 1 CMDQ_THR_PRIO_HIGHEST>;

			gce-subsys = <&gce0 0x14000000 SUBSYS_1400XXXX>,
				     <&gce0 0x14010000 SUBSYS_1401XXXX>,
				     <&gce0 0x14020000 SUBSYS_1402XXXX>;

			mediatek,gce-client-reg = <&gce0 SUBSYS_1400XXXX 0 0x1000>;
		};

		mutex0: disp-mutex0@14001000 {
			compatible = "mediatek,mt8189-disp-mutex";
			reg = <0 0x14001000 0 0x1000>;
			interrupts = <GIC_SPI 332 IRQ_TYPE_LEVEL_HIGH 0>;
			clocks = <&dispsys_config_clk CLK_MM_DISP_MUTEX0>;
			mediatek,gce-client-reg = <&gce0 SUBSYS_1400XXXX 0x1000 0x1000>;
			mediatek,gce-events = <CMDQ_EVENT_DISPSYS_DISP_MUTEX0_ENG_EVENT_0>,
					      <CMDQ_EVENT_DISPSYS_DISP_MUTEX0_ENG_EVENT_1>;
		};

		disp_ovl0_4l: disp-ovl0-4l@14002000 {
			compatible = "mediatek,mt8189-disp-ovl";
			reg = <0 0x14002000 0 0x1000>;
			interrupts = <GIC_SPI 302 IRQ_TYPE_LEVEL_HIGH 0>;
			iommus = <&mm_iommu M4U_L0_P1_DISP_OVL0_4L_RDMA0>,
				 <&mm_iommu M4U_L1_P2_DISP_OVL0_4L_RDMA1>,
				 <&mm_iommu M4U_L0_P3_DISP_OVL0_4L_RDMA2>,
				 <&mm_iommu M4U_L1_P4_DISP_OVL0_4L_RDMA3>,
				 <&mm_iommu M4U_L0_P0_DISP_OVL0_4L_HDR>;
			clocks = <&dispsys_config_clk CLK_MM_DISP_OVL0_4L>;
			mediatek,gce-client-reg = <&gce0 SUBSYS_1400XXXX 0x2000 0x1000>;
		};

		disp_ovl1_4l: disp-ovl1-4l@14003000 {
			compatible = "mediatek,mt8189-disp-ovl";
			reg = <0 0x14003000 0 0x1000>;
			interrupts = <GIC_SPI 304 IRQ_TYPE_LEVEL_HIGH 0>;
			iommus = <&mm_iommu M4U_L1_P1_DISP_OVL1_4L_RDMA0>,
				 <&mm_iommu M4U_L0_P2_DISP_OVL1_4L_RDMA1>,
				 <&mm_iommu M4U_L1_P3_DISP_OVL1_4L_RDMA2>,
				 <&mm_iommu M4U_L0_P4_DISP_OVL1_4L_RDMA3>,
				 <&mm_iommu M4U_L1_P0_DISP_OVL1_4L_HDR>;
			clocks = <&dispsys_config_clk CLK_MM_DISP_OVL1_4L>;
			mediatek,gce-client-reg = <&gce0 SUBSYS_1400XXXX 0x3000 0x1000>;
		};

		disp_rdma0: disp-rdma0@14006000 {
			compatible = "mediatek,mt8195-disp-rdma";
			reg = <0 0x14006000 0 0x1000>;
			interrupts = <GIC_SPI 308 IRQ_TYPE_LEVEL_HIGH 0>;
			clocks = <&dispsys_config_clk CLK_MM_DISP_RDMA0>;
			mediatek,larb = <&smi_larb0>;
			mediatek,smi-id = <0>;
			iommus = <&mm_iommu M4U_L0_P5_DISP_RDMA0>;
			mediatek,gce-client-reg = <&gce0 SUBSYS_1400XXXX 0x6000 0x1000>;
		};

		disp_rdma1: disp-rdma1@14007000 {
			compatible = "mediatek,mt8195-disp-rdma";
			reg = <0 0x14007000 0 0x1000>;
			interrupts = <GIC_SPI 309 IRQ_TYPE_LEVEL_HIGH 0>;
			clocks = <&dispsys_config_clk CLK_MM_DISP_RDMA1>;
			mediatek,larb = <&smi_larb1>;
			mediatek,smi-id = <1>;
			iommus = <&mm_iommu M4U_L1_P5_DISP_RDMA1>;
			mediatek,gce-client-reg = <&gce0 SUBSYS_1400XXXX 0x7000 0x1000>;
		};

		mipi_csi0: mipi-csi0@11f50000 {
			compatible = "mediatek,mt8189-csi-rx";
			reg = <0 0x11f50000 0 0x4000>;
			phy-type = <PHY_TYPE_DPHY>;
			status = "disabled";
			num-lanes = <4>;
			#phy-cells = <1>;
			mediatek,csi-port = "0";
		};

		mipi_csi1: mipi-csi1@11f54000 {
			compatible = "mediatek,mt8189-csi-rx";
			reg = <0 0x11f54000 0 0x4000>;
			phy-type = <PHY_TYPE_DPHY>;
			status = "disabled";
			num-lanes = <2>;
			#phy-cells = <1>;
			mediatek,csi-port = "1";
		};

		seninf_top: seninf-top@1a004000 {
			compatible = "mediatek,mt8189-seninf-core";
			reg = <0 0x1a004000 0 0x8000>;
			reg-names = "base";
			clocks = <&camsys_main_clk CLK_CAM_M_SENINF>,
				 <&topckgen_clk CLK_TOP_SENINF_SEL>,
				 <&topckgen_clk CLK_TOP_SENINF1_SEL>,
				 <&vlp_cksys_clk CLK_VLP_CK_CAMTG0_SEL>,
				 <&vlp_cksys_clk CLK_VLP_CK_CAMTG1_SEL>,
				 <&vlp_cksys_clk CLK_VLP_CK_CAMTG2_SEL>,
				 <&topckgen_clk CLK_TOP_F26M_CK_D2>,
				 <&topckgen_clk CLK_TOP_UNIVPLL_192M_D8>,
				 <&topckgen_clk CLK_TOP_UNIVPLL_D6_D8>,
				 <&topckgen_clk CLK_TOP_UNIVPLL_192M_D4>,
				 <&topckgen_clk CLK_TOP_TCK_26M_MX9>,
				 <&topckgen_clk CLK_TOP_UNIVPLL_192M_D16>,
				 <&topckgen_clk CLK_TOP_UNIVPLL_192M_D32>;
			clock-names = "CAMSYS_SENINF_CGPDN",
				      "TOP_MUX_SENINF",
				      "TOP_MUX_SENINF1",
				      "TOP_MUX_CAMTG",
				      "TOP_MUX_CAMTG1",
				      "TOP_MUX_CAMTG2",
				      "TOP_F26M_CK_D2",
				      "TOP_UNIVP_192M_D8",
				      "TOP_UNIVPLL_D6_D8",
				      "TOP_UNIVP_192M_D4",
				      "TOP_CLK26M",
				      "TOP_UNIVP_192M_D16",
				      "TOP_UNIVP_192M_D32";

			power-domains = <&scpsys MT8189_POWER_DOMAIN_CAM_MAIN>,
					<&scpsys MT8189_POWER_DOMAIN_CSI_RX>;

			seninf_csi_port_0: seninf-csi-port-0 {
				compatible = "mediatek,mt8189-seninf";
				mediatek,csi-port = "0";
				phys = <&mipi_csi0 PHY_TYPE_DPHY>;
				phy-names = "csi0";
				status = "disabled";

				ports {
					#address-cells = <1>;
					#size-cells = <0>;

					port@0 {
						reg = <0>;
					};

					port@1 {
						reg = <1>;
						seninf0_camsv2_endpoint: endpoint {
							remote-endpoint =
								<&camsv2_seninf0_endpoint>;
						};
					};

					port@2 {
						reg = <2>;
						seninf0_camsv3_endpoint: endpoint {
							remote-endpoint =
								<&camsv3_seninf0_endpoint>;
						};
					};

					port@3 {
						reg = <3>;
						seninf0_camsv4_endpoint: endpoint {
							remote-endpoint =
								<&camsv4_seninf0_endpoint>;
						};
					};

					port@4 {
						reg = <4>;
						seninf0_camsv5_endpoint: endpoint {
							remote-endpoint =
								<&camsv5_seninf0_endpoint>;
						};
					};

					port@5 {
						reg = <5>;
						seninf0_camsv6_endpoint: endpoint {
							remote-endpoint =
								<&camsv6_seninf0_endpoint>;
						};
					};

					port@6 {
						reg = <6>;
						seninf0_camsv7_endpoint: endpoint {
							remote-endpoint =
								<&camsv7_seninf0_endpoint>;
						};
					};
				};
			};

			seninf_csi_port_1: seninf-csi-port-1 {
				compatible = "mediatek,mt8189-seninf";
				mediatek,csi-port = "1";
				phys = <&mipi_csi1 PHY_TYPE_DPHY>;
				phy-names = "csi1";
				status = "disabled";

				ports {
					#address-cells = <1>;
					#size-cells = <0>;

					port@0 {
						reg = <0>;
					};

					port@1 {
						reg = <1>;
						seninf1_camsv2_endpoint: endpoint {
							remote-endpoint =
								<&camsv2_seninf1_endpoint>;
						};
					};

					port@2 {
						reg = <2>;
						seninf1_camsv3_endpoint: endpoint {
							remote-endpoint =
								<&camsv3_seninf1_endpoint>;
						};
					};

					port@3 {
						reg = <3>;
						seninf1_camsv4_endpoint: endpoint {
							remote-endpoint =
								<&camsv4_seninf1_endpoint>;
						};
					};

					port@4 {
						reg = <4>;
						seninf1_camsv5_endpoint: endpoint {
							remote-endpoint =
								<&camsv5_seninf1_endpoint>;
						};
					};

					port@5 {
						reg = <5>;
						seninf1_camsv6_endpoint: endpoint {
							remote-endpoint =
								<&camsv6_seninf1_endpoint>;
						};
					};

					port@6 {
						reg = <6>;
						seninf1_camsv7_endpoint: endpoint {
							remote-endpoint =
								<&camsv7_seninf1_endpoint>;
						};
					};
				};
			};
		};

		camsv2: camsv2@1a092000 {
			compatible = "mediatek,mt8189-camsv";
			reg = <0 0x1a092000 0 0x1000>;
			interrupts = <GIC_SPI 143 IRQ_TYPE_LEVEL_HIGH 0>;
			mediatek,cammux-id = <2>;
			clocks = <&camsys_main_clk CLK_CAM_M_CAMSYS_MAIN_CAM>,
				 <&camsys_main_clk CLK_CAM_M_CAMSYS_MAIN_CAMTG>,
				 <&camsys_main_clk CLK_CAM_M_CAMSV1>,
				 <&camsys_main_clk CLK_CAM_M_LARB13>,
				 <&camsys_main_clk CLK_CAM_M_CAM2MM_GALS>,
				 <&topckgen_clk CLK_TOP_CAMTM_SEL>;
			clock-names = "CAMSYS_CAM_CGPDN",
				      "CAMSYS_CAMTG_CGPDN",
				      "CAMSYS_CAMSV_CGPDN",
				      "CAMSYS_LARB_CGPDN",
				      "CAMSYS_MAIN_CAM2MM_GALS_CGPDN",
				      "TOPCKGEN_TOP_MUX_CAMTM";
			iommus = <&mm_iommu M4U_L13_P6_CAMSV_4>;
			power-domains = <&scpsys MT8189_POWER_DOMAIN_CAM_MAIN>;

			ports {
				#address-cells = <1>;
				#size-cells = <0>;
				port@0 {
					reg = <0>;
					camsv2_seninf0_endpoint: endpoint {
						remote-endpoint =
							<&seninf0_camsv2_endpoint>;
					};
				};

				port@1 {
					reg = <1>;
					camsv2_seninf1_endpoint: endpoint {
						remote-endpoint =
							<&seninf1_camsv2_endpoint>;
					};
				};
			};
		};

		camsv3: camsv3@1a093000 {
			compatible = "mediatek,mt8189-camsv";
			reg = <0 0x1a093000 0 0x1000>;
			interrupts = <GIC_SPI 144 IRQ_TYPE_LEVEL_HIGH 0>;
			mediatek,cammux-id = <3>;
			clocks = <&camsys_main_clk CLK_CAM_M_CAMSYS_MAIN_CAM>,
				 <&camsys_main_clk CLK_CAM_M_CAMSYS_MAIN_CAMTG>,
				 <&camsys_main_clk CLK_CAM_M_CAMSV1>,
				 <&camsys_main_clk CLK_CAM_M_LARB13>,
				 <&camsys_main_clk CLK_CAM_M_CAM2MM_GALS>,
				 <&topckgen_clk CLK_TOP_CAMTM_SEL>;
			clock-names = "CAMSYS_CAM_CGPDN",
				      "CAMSYS_CAMTG_CGPDN",
				      "CAMSYS_CAMSV_CGPDN",
				      "CAMSYS_LARB_CGPDN",
				      "CAMSYS_MAIN_CAM2MM_GALS_CGPDN",
				      "TOPCKGEN_TOP_MUX_CAMTM";
			iommus = <&mm_iommu M4U_L13_P6_CAMSV_4>;
			power-domains = <&scpsys MT8189_POWER_DOMAIN_CAM_MAIN>;

			ports {
				#address-cells = <1>;
				#size-cells = <0>;
				port@0 {
					reg = <0>;
					camsv3_seninf0_endpoint: endpoint {
						remote-endpoint =
							<&seninf0_camsv3_endpoint>;
					};
				};

				port@1 {
					reg = <1>;
					camsv3_seninf1_endpoint: endpoint {
						remote-endpoint =
							<&seninf1_camsv3_endpoint>;
					};
				};
			};
		};

		camsv4: camsv4@1a094000 {
			compatible = "mediatek,mt8189-camsv";
			reg = <0 0x1a094000 0 0x1000>;
			interrupts = <GIC_SPI 145 IRQ_TYPE_LEVEL_HIGH 0>;
			mediatek,cammux-id = <4>;
			clocks = <&camsys_main_clk CLK_CAM_M_CAMSYS_MAIN_CAM>,
				 <&camsys_main_clk CLK_CAM_M_CAMSYS_MAIN_CAMTG>,
				 <&camsys_main_clk CLK_CAM_M_CAMSV2>,
				 <&camsys_main_clk CLK_CAM_M_LARB13>,
				 <&camsys_main_clk CLK_CAM_M_CAM2MM_GALS>,
				 <&topckgen_clk CLK_TOP_CAMTM_SEL>;
			clock-names = "CAMSYS_CAM_CGPDN",
				      "CAMSYS_CAMTG_CGPDN",
				      "CAMSYS_CAMSV_CGPDN",
				      "CAMSYS_LARB_CGPDN",
				      "CAMSYS_MAIN_CAM2MM_GALS_CGPDN",
				      "TOPCKGEN_TOP_MUX_CAMTM";
			iommus = <&mm_iommu M4U_L13_P7_CAMSV_5>;
			power-domains = <&scpsys MT8189_POWER_DOMAIN_CAM_MAIN>;

			ports {
				#address-cells = <1>;
				#size-cells = <0>;
				port@0 {
					reg = <0>;
					camsv4_seninf0_endpoint: endpoint {
						remote-endpoint =
							<&seninf0_camsv4_endpoint>;
					};
				};

				port@1 {
					reg = <1>;
					camsv4_seninf1_endpoint: endpoint {
						remote-endpoint =
							<&seninf1_camsv4_endpoint>;
					};
				};
			};
		};

		camsv5: camsv5@1a095000 {
			compatible = "mediatek,mt8189-camsv";
			reg = <0 0x1a095000 0 0x1000>;
			interrupts = <GIC_SPI 146 IRQ_TYPE_LEVEL_HIGH 0>;
			mediatek,cammux-id = <5>;
			clocks = <&camsys_main_clk CLK_CAM_M_CAMSYS_MAIN_CAM>,
				 <&camsys_main_clk CLK_CAM_M_CAMSYS_MAIN_CAMTG>,
				 <&camsys_main_clk CLK_CAM_M_CAMSV2>,
				 <&camsys_main_clk CLK_CAM_M_LARB13>,
				 <&camsys_main_clk CLK_CAM_M_CAM2MM_GALS>,
				 <&topckgen_clk CLK_TOP_CAMTM_SEL>;
			clock-names = "CAMSYS_CAM_CGPDN",
				      "CAMSYS_CAMTG_CGPDN",
				      "CAMSYS_CAMSV_CGPDN",
				      "CAMSYS_LARB_CGPDN",
				      "CAMSYS_MAIN_CAM2MM_GALS_CGPDN",
				      "TOPCKGEN_TOP_MUX_CAMTM";
			iommus = <&mm_iommu M4U_L13_P7_CAMSV_5>;
			power-domains = <&scpsys MT8189_POWER_DOMAIN_CAM_MAIN>;

			ports {
				#address-cells = <1>;
				#size-cells = <0>;
				port@0 {
					reg = <0>;
					camsv5_seninf0_endpoint: endpoint {
						remote-endpoint =
							<&seninf0_camsv5_endpoint>;
					};
				};

				port@1 {
					reg = <1>;
					camsv5_seninf1_endpoint: endpoint {
						remote-endpoint =
							<&seninf1_camsv5_endpoint>;
					};
				};
			};
		};

		camsv6: camsv6@1a096000 {
			compatible = "mediatek,mt8189-camsv";
			reg = <0 0x1a096000 0 0x1000>;
			interrupts = <GIC_SPI 150 IRQ_TYPE_LEVEL_HIGH 0>;
			mediatek,cammux-id = <6>;
			clocks = <&camsys_main_clk CLK_CAM_M_CAMSYS_MAIN_CAM>,
				 <&camsys_main_clk CLK_CAM_M_CAMSYS_MAIN_CAMTG>,
				 <&camsys_main_clk CLK_CAM_M_CAMSV3>,
				 <&camsys_main_clk CLK_CAM_M_LARB13>,
				 <&camsys_main_clk CLK_CAM_M_CAM2MM_GALS>,
				 <&topckgen_clk CLK_TOP_CAMTM_SEL>;
			clock-names = "CAMSYS_CAM_CGPDN",
				      "CAMSYS_CAMTG_CGPDN",
				      "CAMSYS_CAMSV_CGPDN",
				      "CAMSYS_LARB_CGPDN",
				      "CAMSYS_MAIN_CAM2MM_GALS_CGPDN",
				      "TOPCKGEN_TOP_MUX_CAMTM";
			iommus = <&mm_iommu M4U_L13_P8_CAMSV_6>;
			power-domains = <&scpsys MT8189_POWER_DOMAIN_CAM_MAIN>;

			ports {
				#address-cells = <1>;
				#size-cells = <0>;
				port@0 {
					reg = <0>;
					camsv6_seninf0_endpoint: endpoint {
						remote-endpoint =
							<&seninf0_camsv6_endpoint>;
					};
				};

				port@1 {
					reg = <1>;
					camsv6_seninf1_endpoint: endpoint {
						remote-endpoint =
							<&seninf1_camsv6_endpoint>;
					};
				};
			};
		};

		camsv7: camsv7@1a097000 {
			compatible = "mediatek,mt8189-camsv";
			reg = <0 0x1a097000 0 0x1000>;
			interrupts = <GIC_SPI 151 IRQ_TYPE_LEVEL_HIGH 0>;
			mediatek,cammux-id = <7>;
			clocks = <&camsys_main_clk CLK_CAM_M_CAMSYS_MAIN_CAM>,
				 <&camsys_main_clk CLK_CAM_M_CAMSYS_MAIN_CAMTG>,
				 <&camsys_main_clk CLK_CAM_M_CAMSV3>,
				 <&camsys_main_clk CLK_CAM_M_LARB13>,
				 <&camsys_main_clk CLK_CAM_M_CAM2MM_GALS>,
				 <&topckgen_clk CLK_TOP_CAMTM_SEL>;
			clock-names = "CAMSYS_CAM_CGPDN",
				      "CAMSYS_CAMTG_CGPDN",
				      "CAMSYS_CAMSV_CGPDN",
				      "CAMSYS_LARB_CGPDN",
				      "CAMSYS_MAIN_CAM2MM_GALS_CGPDN",
				      "TOPCKGEN_TOP_MUX_CAMTM";
			iommus = <&mm_iommu M4U_L13_P8_CAMSV_6>;
			power-domains = <&scpsys MT8189_POWER_DOMAIN_CAM_MAIN>;

			ports {
				#address-cells = <1>;
				#size-cells = <0>;
				port@0 {
					reg = <0>;
					camsv7_seninf0_endpoint: endpoint {
						remote-endpoint =
							<&seninf0_camsv7_endpoint>;
					};
				};

				port@1 {
					reg = <1>;
					camsv7_seninf1_endpoint: endpoint {
						remote-endpoint =
							<&seninf1_camsv7_endpoint>;
					};
				};
			};
		};

		mutex1: mdp-mutex0@1f001000 {
			compatible = "mediatek,mt8189-mdp-mutex";
			reg = <0 0x1f001000 0 0x1000>;
			clocks = <&mdpsys_config_clk CLK_MDP_MUTEX0>;
		};

		dma-controller@1f003000 {
			compatible = "mediatek,mt8189-mdp3-rdma";
			reg = <0 0x1f003000 0 0x1000>;
			mediatek,gce-client-reg = <&gce0 SUBSYS_NO_SUPPORT 0x3000 0x1000>;
			mediatek,gce-events = <CMDQ_EVENT_MMLSYS_MDP_RDMA0_SOF>,
					      <CMDQ_EVENT_MMLSYS_MDP_RDMA0_FRAME_DONE>;
			power-domains = <&scpsys MT8189_POWER_DOMAIN_MDP0>;
			iommus = <&mm_iommu M4U_L2_P0_MDP_RDMA0>;
			clocks = <&mdpsys_config_clk CLK_MDP_RDMA0>,
				 <&mdpsys_config_clk CLK_MDPSYS_CONFIG>;
			mboxes = <&gce0 16 CMDQ_THR_PRIO_1>,
				 <&gce0 17 CMDQ_THR_PRIO_1>,
				 <&gce0 18 CMDQ_THR_PRIO_1>;
			#dma-cells = <1>;
		};

		dma-controller@1f004000 {
			compatible = "mediatek,mt8189-mdp3-rdma";
			reg = <0 0x1f004000 0 0x1000>;
			mediatek,gce-client-reg = <&gce0 SUBSYS_NO_SUPPORT 0x4000 0x1000>;
			mediatek,gce-events = <CMDQ_EVENT_MMLSYS_MDP_RDMA1_SOF>,
					      <CMDQ_EVENT_MMLSYS_MDP_RDMA1_FRAME_DONE>;
			power-domains = <&scpsys MT8189_POWER_DOMAIN_MDP0>;
			iommus = <&mm_iommu M4U_L2_P1_MDP_RDMA1>;
			clocks = <&mdpsys_config_clk CLK_MDP_RDMA1>;
			#dma-cells = <1>;
		};

		display@1f005000 {
			compatible = "mediatek,mt8195-mdp3-hdr";
			reg = <0 0x1f005000 0 0x1000>;
			mediatek,gce-client-reg = <&gce0 SUBSYS_NO_SUPPORT 0x5000 0x1000>;
			clocks = <&mdpsys_config_clk CLK_MDP_HDR0>;
		};

		display@1f006000 {
			compatible = "mediatek,mt8195-mdp3-hdr";
			reg = <0 0x1f006000 0 0x1000>;
			mediatek,gce-client-reg = <&gce0 SUBSYS_NO_SUPPORT 0x6000 0x1000>;
			clocks = <&mdpsys_config_clk CLK_MDP_HDR1>;
		};

		display@1f007000 {
			compatible = "mediatek,mt8195-mdp3-aal";
			reg = <0 0x1f007000 0 0x1000>;
			mediatek,gce-client-reg = <&gce0 SUBSYS_NO_SUPPORT 0x7000 0x1000>;
			clocks = <&mdpsys_config_clk CLK_MDP_AAL0>;
		};

		display@1f008000 {
			compatible = "mediatek,mt8195-mdp3-aal";
			reg = <0 0x1f008000 0 0x1000>;
			mediatek,gce-client-reg = <&gce0 SUBSYS_NO_SUPPORT 0x8000 0x1000>;
			clocks = <&mdpsys_config_clk CLK_MDP_AAL1>;
		};

		display@1f009000 {
			compatible = "mediatek,mt8183-mdp3-rsz";
			reg = <0 0x1f009000 0 0x1000>;
			mediatek,gce-client-reg = <&gce0 SUBSYS_NO_SUPPORT 0x9000 0x1000>;
			mediatek,gce-events = <CMDQ_EVENT_MAX>,
					      <CMDQ_EVENT_MMLSYS_MDP_RSZ0_FRAME_DONE>;
			clocks = <&mdpsys_config_clk CLK_MDP_RSZ0>;
		};

		display@1f00a000 {
			compatible = "mediatek,mt8183-mdp3-rsz";
			reg = <0 0x1f00a000 0 0x1000>;
			mediatek,gce-client-reg = <&gce0 SUBSYS_NO_SUPPORT 0xa000 0x1000>;
			mediatek,gce-events = <CMDQ_EVENT_MAX>,
					      <CMDQ_EVENT_MMLSYS_MDP_RSZ0_FRAME_DONE>;
			clocks = <&mdpsys_config_clk CLK_MDP_RSZ0>;
		};

		display@1f00b000 {
			compatible = "mediatek,mt8195-mdp3-tdshp";
			reg = <0 0x1f00b000 0 0x1000>;
			mediatek,gce-client-reg = <&gce0 SUBSYS_NO_SUPPORT 0xb000 0x1000>;
			clocks = <&mdpsys_config_clk CLK_MDP_TDSHP0>;
		};

		display@1f00c000 {
			compatible = "mediatek,mt8195-mdp3-tdshp";
			reg = <0 0x1f00c000 0 0x1000>;
			mediatek,gce-client-reg = <&gce0 SUBSYS_NO_SUPPORT 0xc000 0x1000>;
			clocks = <&mdpsys_config_clk CLK_MDP_TDSHP1>;
		};

		display@1f00d000 {
			compatible = "mediatek,mt8195-mdp3-color";
			reg = <0 0x1f00d000 0 0x1000>;
			mediatek,gce-client-reg = <&gce0 SUBSYS_NO_SUPPORT 0xd000 0x1000>;
			clocks = <&mdpsys_config_clk CLK_MDP_COLOR0>;
		};

		display@1f00e000 {
			compatible = "mediatek,mt8195-mdp3-color";
			reg = <0 0x1f00e000 0 0x1000>;
			mediatek,gce-client-reg = <&gce0 SUBSYS_NO_SUPPORT 0xe000 0x1000>;
			clocks = <&mdpsys_config_clk CLK_MDP_COLOR1>;
		};

		dma-controller@1f00f000 {
			compatible = "mediatek,mt8195-mdp3-wrot", "mediatek,mt8183-mdp3-wrot";
			reg = <0 0x1f00f000 0 0x1000>;
			mediatek,gce-client-reg = <&gce0 SUBSYS_NO_SUPPORT 0xf000 0x1000>;
			mediatek,gce-events = <CMDQ_EVENT_MMLSYS_MDP_WROT0_SOF>,
					      <CMDQ_EVENT_MMLSYS_MDP_WROT0_FRAME_DONE>;
			power-domains = <&scpsys MT8189_POWER_DOMAIN_MDP0>;
			iommus = <&mm_iommu M4U_L2_P2_MDP_WROT0>;
			clocks = <&mdpsys_config_clk CLK_MDP_WROT0>;
			#dma-cells = <1>;
		};

		dma-controller@1f010000 {
			compatible = "mediatek,mt8195-mdp3-wrot", "mediatek,mt8183-mdp3-wrot";
			reg = <0 0x1f010000 0 0x1000>;
			mediatek,gce-client-reg = <&gce0 SUBSYS_NO_SUPPORT 0x0000 0x1000>;
			mediatek,gce-events = <CMDQ_EVENT_MMLSYS_MDP_WROT1_SOF>,
					      <CMDQ_EVENT_MMLSYS_MDP_WROT1_FRAME_DONE>;
			power-domains = <&scpsys MT8189_POWER_DOMAIN_MDP0>;
			iommus = <&mm_iommu M4U_L2_P3_MDP_WROT1>;
			clocks = <&mdpsys_config_clk CLK_MDP_WROT1>;
			#dma-cells = <1>;
		};

		dma-controller@1f011000 {
			compatible = "mediatek,mt8189-mdp3-rdma";
			reg = <0 0x1f011000 0 0x1000>;
			mediatek,gce-client-reg = <&gce0 SUBSYS_NO_SUPPORT 0x1000 0x1000>;
			mediatek,gce-events = <CMDQ_EVENT_MMLSYS_MDP_RDMA2_SOF>,
					      <CMDQ_EVENT_MMLSYS_MDP_RDMA2_FRAME_DONE>;
			power-domains = <&scpsys MT8189_POWER_DOMAIN_MDP0>;
			iommus = <&mm_iommu M4U_L2_P6_MDP_RDMA2>;
			clocks = <&mdpsys_config_clk CLK_MDP_RDMA2>;
			#dma-cells = <1>;
		};

		dma-controller@1f012000 {
			compatible = "mediatek,mt8189-mdp3-rdma";
			reg = <0 0x1f012000 0 0x1000>;
			mediatek,gce-client-reg = <&gce0 SUBSYS_NO_SUPPORT 0x2000 0x1000>;
			mediatek,gce-events = <CMDQ_EVENT_MMLSYS_MDP_RDMA3_SOF>,
					      <CMDQ_EVENT_MMLSYS_MDP_RDMA3_FRAME_DONE>;
			power-domains = <&scpsys MT8189_POWER_DOMAIN_MDP0>;
			iommus = <&mm_iommu M4U_L2_P7_MDP_RDMA3>;
			clocks = <&mdpsys_config_clk CLK_MDP_RDMA3>;
			#dma-cells = <1>;
		};

		display@1f013000 {
			compatible = "mediatek,mt8183-mdp3-rsz";
			reg = <0 0x1f013000 0 0x1000>;
			mediatek,gce-client-reg = <&gce0 SUBSYS_NO_SUPPORT 0x3000 0x1000>;
			mediatek,gce-events = <CMDQ_EVENT_MAX>,
					      <CMDQ_EVENT_MMLSYS_MDP_RSZ2_FRAME_DONE>;
			clocks = <&mdpsys_config_clk CLK_MDP_RSZ2>;
		};

		display@1f014000 {
			compatible = "mediatek,mt8183-mdp3-rsz";
			reg = <0 0x1f014000 0 0x1000>;
			mediatek,gce-client-reg = <&gce0 SUBSYS_NO_SUPPORT 0x4000 0x1000>;
			mediatek,gce-events = <CMDQ_EVENT_MAX>,
					      <CMDQ_EVENT_MMLSYS_MDP_RSZ3_FRAME_DONE>;
			clocks = <&mdpsys_config_clk CLK_MDP_RSZ3>;
		};

		dma-controller@1f015000 {
			compatible = "mediatek,mt8195-mdp3-wrot", "mediatek,mt8183-mdp3-wrot";
			reg = <0 0x1f015000 0 0x1000>;
			mediatek,gce-client-reg = <&gce0 SUBSYS_NO_SUPPORT 0x5000 0x1000>;
			mediatek,gce-events = <CMDQ_EVENT_MMLSYS_MDP_WROT2_SOF>,
					      <CMDQ_EVENT_MMLSYS_MDP_WROT2_FRAME_DONE>;
			power-domains = <&scpsys MT8189_POWER_DOMAIN_MDP0>;
			iommus = <&mm_iommu M4U_L2_P8_MDP_WROT2>;
			clocks = <&mdpsys_config_clk CLK_MDP_WROT2>;
			#dma-cells = <1>;
		};

		dma-controller@1f016000 {
			compatible = "mediatek,mt8195-mdp3-wrot", "mediatek,mt8183-mdp3-wrot";
			reg = <0 0x1f016000 0 0x1000>;
			mediatek,gce-client-reg = <&gce0 SUBSYS_NO_SUPPORT 0x6000 0x1000>;
			mediatek,gce-events = <CMDQ_EVENT_MMLSYS_MDP_WROT3_SOF>,
					      <CMDQ_EVENT_MMLSYS_MDP_WROT3_FRAME_DONE>;
			power-domains = <&scpsys MT8189_POWER_DOMAIN_MDP0>;
			iommus = <&mm_iommu M4U_L2_P9_MDP_WROT3>;
			clocks = <&mdpsys_config_clk CLK_MDP_WROT3>;
			#dma-cells = <1>;
		};

		display@1f81a000 {
			compatible = "mediatek,mt8195-mdp3-fg";
			reg = <0 0x1f81a000 0 0x1000>;
			mediatek,gce-client-reg = <&gce0 SUBSYS_NO_SUPPORT 0xa000 0x1000>;
		};

		display@1f81b000 {
			compatible = "mediatek,mt8195-mdp3-fg";
			reg = <0 0x1f81b000 0 0x1000>;
			mediatek,gce-client-reg = <&gce0 SUBSYS_NO_SUPPORT 0xb000 0x1000>;
		};
	};
};
